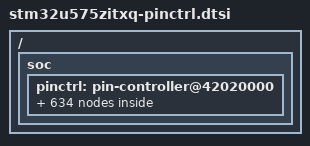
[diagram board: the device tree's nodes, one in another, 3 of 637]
/*
 * NOTE: Autogenerated file using genpinctrl.py
 *
 * SPDX-License-Identifier: Apache-2.0
 */

#include <zephyr/dt-bindings/pinctrl/stm32-pinctrl.h>

/ {
	soc {
		pinctrl: pin-controller@42020000 {

			/* ADC_IN / ADC_INN / ADC_INP */

			/omit-if-no-ref/ adc1_in5_pa0: adc1_in5_pa0 {
				pinmux = <STM32_PINMUX('A', 0, ANALOG)>;
			};

			/omit-if-no-ref/ adc1_in6_pa1: adc1_in6_pa1 {
				pinmux = <STM32_PINMUX('A', 1, ANALOG)>;
			};

			/omit-if-no-ref/ adc1_in7_pa2: adc1_in7_pa2 {
				pinmux = <STM32_PINMUX('A', 2, ANALOG)>;
			};

			/omit-if-no-ref/ adc1_in8_pa3: adc1_in8_pa3 {
				pinmux = <STM32_PINMUX('A', 3, ANALOG)>;
			};

			/omit-if-no-ref/ adc1_in9_pa4: adc1_in9_pa4 {
				pinmux = <STM32_PINMUX('A', 4, ANALOG)>;
			};

			/omit-if-no-ref/ adc1_in10_pa5: adc1_in10_pa5 {
				pinmux = <STM32_PINMUX('A', 5, ANALOG)>;
			};

			/omit-if-no-ref/ adc1_in11_pa6: adc1_in11_pa6 {
				pinmux = <STM32_PINMUX('A', 6, ANALOG)>;
			};

			/omit-if-no-ref/ adc1_in12_pa7: adc1_in12_pa7 {
				pinmux = <STM32_PINMUX('A', 7, ANALOG)>;
			};

			/omit-if-no-ref/ adc1_in15_pb0: adc1_in15_pb0 {
				pinmux = <STM32_PINMUX('B', 0, ANALOG)>;
			};

			/omit-if-no-ref/ adc1_in16_pb1: adc1_in16_pb1 {
				pinmux = <STM32_PINMUX('B', 1, ANALOG)>;
			};

			/omit-if-no-ref/ adc1_in17_pb2: adc1_in17_pb2 {
				pinmux = <STM32_PINMUX('B', 2, ANALOG)>;
			};

			/omit-if-no-ref/ adc1_in1_pc0: adc1_in1_pc0 {
				pinmux = <STM32_PINMUX('C', 0, ANALOG)>;
			};

			/omit-if-no-ref/ adc1_in2_pc1: adc1_in2_pc1 {
				pinmux = <STM32_PINMUX('C', 1, ANALOG)>;
			};

			/omit-if-no-ref/ adc1_in3_pc2: adc1_in3_pc2 {
				pinmux = <STM32_PINMUX('C', 2, ANALOG)>;
			};

			/omit-if-no-ref/ adc1_in4_pc3: adc1_in4_pc3 {
				pinmux = <STM32_PINMUX('C', 3, ANALOG)>;
			};

			/omit-if-no-ref/ adc4_in9_pa4: adc4_in9_pa4 {
				pinmux = <STM32_PINMUX('A', 4, ANALOG)>;
			};

			/omit-if-no-ref/ adc4_in10_pa5: adc4_in10_pa5 {
				pinmux = <STM32_PINMUX('A', 5, ANALOG)>;
			};

			/omit-if-no-ref/ adc4_in11_pa6: adc4_in11_pa6 {
				pinmux = <STM32_PINMUX('A', 6, ANALOG)>;
			};

			/omit-if-no-ref/ adc4_in20_pa7: adc4_in20_pa7 {
				pinmux = <STM32_PINMUX('A', 7, ANALOG)>;
			};

			/omit-if-no-ref/ adc4_in18_pb0: adc4_in18_pb0 {
				pinmux = <STM32_PINMUX('B', 0, ANALOG)>;
			};

			/omit-if-no-ref/ adc4_in19_pb1: adc4_in19_pb1 {
				pinmux = <STM32_PINMUX('B', 1, ANALOG)>;
			};

			/omit-if-no-ref/ adc4_in1_pc0: adc4_in1_pc0 {
				pinmux = <STM32_PINMUX('C', 0, ANALOG)>;
			};

			/omit-if-no-ref/ adc4_in2_pc1: adc4_in2_pc1 {
				pinmux = <STM32_PINMUX('C', 1, ANALOG)>;
			};

			/omit-if-no-ref/ adc4_in3_pc2: adc4_in3_pc2 {
				pinmux = <STM32_PINMUX('C', 2, ANALOG)>;
			};

			/omit-if-no-ref/ adc4_in4_pc3: adc4_in4_pc3 {
				pinmux = <STM32_PINMUX('C', 3, ANALOG)>;
			};

			/omit-if-no-ref/ adc4_in15_pd11: adc4_in15_pd11 {
				pinmux = <STM32_PINMUX('D', 11, ANALOG)>;
			};

			/omit-if-no-ref/ adc4_in16_pd12: adc4_in16_pd12 {
				pinmux = <STM32_PINMUX('D', 12, ANALOG)>;
			};

			/omit-if-no-ref/ adc4_in17_pd13: adc4_in17_pd13 {
				pinmux = <STM32_PINMUX('D', 13, ANALOG)>;
			};

			/omit-if-no-ref/ adc4_in5_pf14: adc4_in5_pf14 {
				pinmux = <STM32_PINMUX('F', 14, ANALOG)>;
			};

			/omit-if-no-ref/ adc4_in6_pf15: adc4_in6_pf15 {
				pinmux = <STM32_PINMUX('F', 15, ANALOG)>;
			};

			/omit-if-no-ref/ adc4_in7_pg0: adc4_in7_pg0 {
				pinmux = <STM32_PINMUX('G', 0, ANALOG)>;
			};

			/omit-if-no-ref/ adc4_in8_pg1: adc4_in8_pg1 {
				pinmux = <STM32_PINMUX('G', 1, ANALOG)>;
			};

			/* Analog */

			/omit-if-no-ref/ analog_pa0: analog_pa0 {
				pinmux = <STM32_PINMUX('A', 0, ANALOG)>;
			};

			/omit-if-no-ref/ analog_pa1: analog_pa1 {
				pinmux = <STM32_PINMUX('A', 1, ANALOG)>;
			};

			/omit-if-no-ref/ analog_pa2: analog_pa2 {
				pinmux = <STM32_PINMUX('A', 2, ANALOG)>;
			};

			/omit-if-no-ref/ analog_pa3: analog_pa3 {
				pinmux = <STM32_PINMUX('A', 3, ANALOG)>;
			};

			/omit-if-no-ref/ analog_pa4: analog_pa4 {
				pinmux = <STM32_PINMUX('A', 4, ANALOG)>;
			};

			/omit-if-no-ref/ analog_pa5: analog_pa5 {
				pinmux = <STM32_PINMUX('A', 5, ANALOG)>;
			};

			/omit-if-no-ref/ analog_pa6: analog_pa6 {
				pinmux = <STM32_PINMUX('A', 6, ANALOG)>;
			};

			/omit-if-no-ref/ analog_pa7: analog_pa7 {
				pinmux = <STM32_PINMUX('A', 7, ANALOG)>;
			};

			/omit-if-no-ref/ analog_pa8: analog_pa8 {
				pinmux = <STM32_PINMUX('A', 8, ANALOG)>;
			};

			/omit-if-no-ref/ analog_pa9: analog_pa9 {
				pinmux = <STM32_PINMUX('A', 9, ANALOG)>;
			};

			/omit-if-no-ref/ analog_pa10: analog_pa10 {
				pinmux = <STM32_PINMUX('A', 10, ANALOG)>;
			};

			/omit-if-no-ref/ analog_pa11: analog_pa11 {
				pinmux = <STM32_PINMUX('A', 11, ANALOG)>;
			};

			/omit-if-no-ref/ analog_pa12: analog_pa12 {
				pinmux = <STM32_PINMUX('A', 12, ANALOG)>;
			};

			/omit-if-no-ref/ analog_pa13: analog_pa13 {
				pinmux = <STM32_PINMUX('A', 13, ANALOG)>;
			};

			/omit-if-no-ref/ analog_pa14: analog_pa14 {
				pinmux = <STM32_PINMUX('A', 14, ANALOG)>;
			};

			/omit-if-no-ref/ analog_pa15: analog_pa15 {
				pinmux = <STM32_PINMUX('A', 15, ANALOG)>;
			};

			/omit-if-no-ref/ analog_pb0: analog_pb0 {
				pinmux = <STM32_PINMUX('B', 0, ANALOG)>;
			};

			/omit-if-no-ref/ analog_pb1: analog_pb1 {
				pinmux = <STM32_PINMUX('B', 1, ANALOG)>;
			};

			/omit-if-no-ref/ analog_pb2: analog_pb2 {
				pinmux = <STM32_PINMUX('B', 2, ANALOG)>;
			};

			/omit-if-no-ref/ analog_pb3: analog_pb3 {
				pinmux = <STM32_PINMUX('B', 3, ANALOG)>;
			};

			/omit-if-no-ref/ analog_pb4: analog_pb4 {
				pinmux = <STM32_PINMUX('B', 4, ANALOG)>;
			};

			/omit-if-no-ref/ analog_pb5: analog_pb5 {
				pinmux = <STM32_PINMUX('B', 5, ANALOG)>;
			};

			/omit-if-no-ref/ analog_pb6: analog_pb6 {
				pinmux = <STM32_PINMUX('B', 6, ANALOG)>;
			};

			/omit-if-no-ref/ analog_pb7: analog_pb7 {
				pinmux = <STM32_PINMUX('B', 7, ANALOG)>;
			};

			/omit-if-no-ref/ analog_pb8: analog_pb8 {
				pinmux = <STM32_PINMUX('B', 8, ANALOG)>;
			};

			/omit-if-no-ref/ analog_pb9: analog_pb9 {
				pinmux = <STM32_PINMUX('B', 9, ANALOG)>;
			};

			/omit-if-no-ref/ analog_pb10: analog_pb10 {
				pinmux = <STM32_PINMUX('B', 10, ANALOG)>;
			};

			/omit-if-no-ref/ analog_pb11: analog_pb11 {
				pinmux = <STM32_PINMUX('B', 11, ANALOG)>;
			};

			/omit-if-no-ref/ analog_pb13: analog_pb13 {
				pinmux = <STM32_PINMUX('B', 13, ANALOG)>;
			};

			/omit-if-no-ref/ analog_pb14: analog_pb14 {
				pinmux = <STM32_PINMUX('B', 14, ANALOG)>;
			};

			/omit-if-no-ref/ analog_pb15: analog_pb15 {
				pinmux = <STM32_PINMUX('B', 15, ANALOG)>;
			};

			/omit-if-no-ref/ analog_pc0: analog_pc0 {
				pinmux = <STM32_PINMUX('C', 0, ANALOG)>;
			};

			/omit-if-no-ref/ analog_pc1: analog_pc1 {
				pinmux = <STM32_PINMUX('C', 1, ANALOG)>;
			};

			/omit-if-no-ref/ analog_pc2: analog_pc2 {
				pinmux = <STM32_PINMUX('C', 2, ANALOG)>;
			};

			/omit-if-no-ref/ analog_pc3: analog_pc3 {
				pinmux = <STM32_PINMUX('C', 3, ANALOG)>;
			};

			/omit-if-no-ref/ analog_pc6: analog_pc6 {
				pinmux = <STM32_PINMUX('C', 6, ANALOG)>;
			};

			/omit-if-no-ref/ analog_pc7: analog_pc7 {
				pinmux = <STM32_PINMUX('C', 7, ANALOG)>;
			};

			/omit-if-no-ref/ analog_pc8: analog_pc8 {
				pinmux = <STM32_PINMUX('C', 8, ANALOG)>;
			};

			/omit-if-no-ref/ analog_pc9: analog_pc9 {
				pinmux = <STM32_PINMUX('C', 9, ANALOG)>;
			};

			/omit-if-no-ref/ analog_pc10: analog_pc10 {
				pinmux = <STM32_PINMUX('C', 10, ANALOG)>;
			};

			/omit-if-no-ref/ analog_pc11: analog_pc11 {
				pinmux = <STM32_PINMUX('C', 11, ANALOG)>;
			};

			/omit-if-no-ref/ analog_pc12: analog_pc12 {
				pinmux = <STM32_PINMUX('C', 12, ANALOG)>;
			};

			/omit-if-no-ref/ analog_pc13: analog_pc13 {
				pinmux = <STM32_PINMUX('C', 13, ANALOG)>;
			};

			/omit-if-no-ref/ analog_pc14: analog_pc14 {
				pinmux = <STM32_PINMUX('C', 14, ANALOG)>;
			};

			/omit-if-no-ref/ analog_pc15: analog_pc15 {
				pinmux = <STM32_PINMUX('C', 15, ANALOG)>;
			};

			/omit-if-no-ref/ analog_pd0: analog_pd0 {
				pinmux = <STM32_PINMUX('D', 0, ANALOG)>;
			};

			/omit-if-no-ref/ analog_pd1: analog_pd1 {
				pinmux = <STM32_PINMUX('D', 1, ANALOG)>;
			};

			/omit-if-no-ref/ analog_pd2: analog_pd2 {
				pinmux = <STM32_PINMUX('D', 2, ANALOG)>;
			};

			/omit-if-no-ref/ analog_pd3: analog_pd3 {
				pinmux = <STM32_PINMUX('D', 3, ANALOG)>;
			};

			/omit-if-no-ref/ analog_pd4: analog_pd4 {
				pinmux = <STM32_PINMUX('D', 4, ANALOG)>;
			};

			/omit-if-no-ref/ analog_pd5: analog_pd5 {
				pinmux = <STM32_PINMUX('D', 5, ANALOG)>;
			};

			/omit-if-no-ref/ analog_pd6: analog_pd6 {
				pinmux = <STM32_PINMUX('D', 6, ANALOG)>;
			};

			/omit-if-no-ref/ analog_pd7: analog_pd7 {
				pinmux = <STM32_PINMUX('D', 7, ANALOG)>;
			};

			/omit-if-no-ref/ analog_pd8: analog_pd8 {
				pinmux = <STM32_PINMUX('D', 8, ANALOG)>;
			};

			/omit-if-no-ref/ analog_pd9: analog_pd9 {
				pinmux = <STM32_PINMUX('D', 9, ANALOG)>;
			};

			/omit-if-no-ref/ analog_pd10: analog_pd10 {
				pinmux = <STM32_PINMUX('D', 10, ANALOG)>;
			};

			/omit-if-no-ref/ analog_pd11: analog_pd11 {
				pinmux = <STM32_PINMUX('D', 11, ANALOG)>;
			};

			/omit-if-no-ref/ analog_pd12: analog_pd12 {
				pinmux = <STM32_PINMUX('D', 12, ANALOG)>;
			};

			/omit-if-no-ref/ analog_pd13: analog_pd13 {
				pinmux = <STM32_PINMUX('D', 13, ANALOG)>;
			};

			/omit-if-no-ref/ analog_pd14: analog_pd14 {
				pinmux = <STM32_PINMUX('D', 14, ANALOG)>;
			};

			/omit-if-no-ref/ analog_pd15: analog_pd15 {
				pinmux = <STM32_PINMUX('D', 15, ANALOG)>;
			};

			/omit-if-no-ref/ analog_pe0: analog_pe0 {
				pinmux = <STM32_PINMUX('E', 0, ANALOG)>;
			};

			/omit-if-no-ref/ analog_pe1: analog_pe1 {
				pinmux = <STM32_PINMUX('E', 1, ANALOG)>;
			};

			/omit-if-no-ref/ analog_pe2: analog_pe2 {
				pinmux = <STM32_PINMUX('E', 2, ANALOG)>;
			};

			/omit-if-no-ref/ analog_pe3: analog_pe3 {
				pinmux = <STM32_PINMUX('E', 3, ANALOG)>;
			};

			/omit-if-no-ref/ analog_pe4: analog_pe4 {
				pinmux = <STM32_PINMUX('E', 4, ANALOG)>;
			};

			/omit-if-no-ref/ analog_pe5: analog_pe5 {
				pinmux = <STM32_PINMUX('E', 5, ANALOG)>;
			};

			/omit-if-no-ref/ analog_pe6: analog_pe6 {
				pinmux = <STM32_PINMUX('E', 6, ANALOG)>;
			};

			/omit-if-no-ref/ analog_pe7: analog_pe7 {
				pinmux = <STM32_PINMUX('E', 7, ANALOG)>;
			};

			/omit-if-no-ref/ analog_pe8: analog_pe8 {
				pinmux = <STM32_PINMUX('E', 8, ANALOG)>;
			};

			/omit-if-no-ref/ analog_pe9: analog_pe9 {
				pinmux = <STM32_PINMUX('E', 9, ANALOG)>;
			};

			/omit-if-no-ref/ analog_pe10: analog_pe10 {
				pinmux = <STM32_PINMUX('E', 10, ANALOG)>;
			};

			/omit-if-no-ref/ analog_pe11: analog_pe11 {
				pinmux = <STM32_PINMUX('E', 11, ANALOG)>;
			};

			/omit-if-no-ref/ analog_pe12: analog_pe12 {
				pinmux = <STM32_PINMUX('E', 12, ANALOG)>;
			};

			/omit-if-no-ref/ analog_pe13: analog_pe13 {
				pinmux = <STM32_PINMUX('E', 13, ANALOG)>;
			};

			/omit-if-no-ref/ analog_pe14: analog_pe14 {
				pinmux = <STM32_PINMUX('E', 14, ANALOG)>;
			};

			/omit-if-no-ref/ analog_pe15: analog_pe15 {
				pinmux = <STM32_PINMUX('E', 15, ANALOG)>;
			};

			/omit-if-no-ref/ analog_pf0: analog_pf0 {
				pinmux = <STM32_PINMUX('F', 0, ANALOG)>;
			};

			/omit-if-no-ref/ analog_pf1: analog_pf1 {
				pinmux = <STM32_PINMUX('F', 1, ANALOG)>;
			};

			/omit-if-no-ref/ analog_pf2: analog_pf2 {
				pinmux = <STM32_PINMUX('F', 2, ANALOG)>;
			};

			/omit-if-no-ref/ analog_pf3: analog_pf3 {
				pinmux = <STM32_PINMUX('F', 3, ANALOG)>;
			};

			/omit-if-no-ref/ analog_pf4: analog_pf4 {
				pinmux = <STM32_PINMUX('F', 4, ANALOG)>;
			};

			/omit-if-no-ref/ analog_pf5: analog_pf5 {
				pinmux = <STM32_PINMUX('F', 5, ANALOG)>;
			};

			/omit-if-no-ref/ analog_pf6: analog_pf6 {
				pinmux = <STM32_PINMUX('F', 6, ANALOG)>;
			};

			/omit-if-no-ref/ analog_pf7: analog_pf7 {
				pinmux = <STM32_PINMUX('F', 7, ANALOG)>;
			};

			/omit-if-no-ref/ analog_pf8: analog_pf8 {
				pinmux = <STM32_PINMUX('F', 8, ANALOG)>;
			};

			/omit-if-no-ref/ analog_pf9: analog_pf9 {
				pinmux = <STM32_PINMUX('F', 9, ANALOG)>;
			};

			/omit-if-no-ref/ analog_pf10: analog_pf10 {
				pinmux = <STM32_PINMUX('F', 10, ANALOG)>;
			};

			/omit-if-no-ref/ analog_pf11: analog_pf11 {
				pinmux = <STM32_PINMUX('F', 11, ANALOG)>;
			};

			/omit-if-no-ref/ analog_pf12: analog_pf12 {
				pinmux = <STM32_PINMUX('F', 12, ANALOG)>;
			};

			/omit-if-no-ref/ analog_pf13: analog_pf13 {
				pinmux = <STM32_PINMUX('F', 13, ANALOG)>;
			};

			/omit-if-no-ref/ analog_pf14: analog_pf14 {
				pinmux = <STM32_PINMUX('F', 14, ANALOG)>;
			};

			/omit-if-no-ref/ analog_pf15: analog_pf15 {
				pinmux = <STM32_PINMUX('F', 15, ANALOG)>;
			};

			/omit-if-no-ref/ analog_pg0: analog_pg0 {
				pinmux = <STM32_PINMUX('G', 0, ANALOG)>;
			};

			/omit-if-no-ref/ analog_pg1: analog_pg1 {
				pinmux = <STM32_PINMUX('G', 1, ANALOG)>;
			};

			/omit-if-no-ref/ analog_pg2: analog_pg2 {
				pinmux = <STM32_PINMUX('G', 2, ANALOG)>;
			};

			/omit-if-no-ref/ analog_pg3: analog_pg3 {
				pinmux = <STM32_PINMUX('G', 3, ANALOG)>;
			};

			/omit-if-no-ref/ analog_pg4: analog_pg4 {
				pinmux = <STM32_PINMUX('G', 4, ANALOG)>;
			};

			/omit-if-no-ref/ analog_pg5: analog_pg5 {
				pinmux = <STM32_PINMUX('G', 5, ANALOG)>;
			};

			/omit-if-no-ref/ analog_pg6: analog_pg6 {
				pinmux = <STM32_PINMUX('G', 6, ANALOG)>;
			};

			/omit-if-no-ref/ analog_pg7: analog_pg7 {
				pinmux = <STM32_PINMUX('G', 7, ANALOG)>;
			};

			/omit-if-no-ref/ analog_pg8: analog_pg8 {
				pinmux = <STM32_PINMUX('G', 8, ANALOG)>;
			};

			/omit-if-no-ref/ analog_pg9: analog_pg9 {
				pinmux = <STM32_PINMUX('G', 9, ANALOG)>;
			};

			/omit-if-no-ref/ analog_pg10: analog_pg10 {
				pinmux = <STM32_PINMUX('G', 10, ANALOG)>;
			};

			/omit-if-no-ref/ analog_pg12: analog_pg12 {
				pinmux = <STM32_PINMUX('G', 12, ANALOG)>;
			};

			/omit-if-no-ref/ analog_pg13: analog_pg13 {
				pinmux = <STM32_PINMUX('G', 13, ANALOG)>;
			};

			/omit-if-no-ref/ analog_pg14: analog_pg14 {
				pinmux = <STM32_PINMUX('G', 14, ANALOG)>;
			};

			/omit-if-no-ref/ analog_pg15: analog_pg15 {
				pinmux = <STM32_PINMUX('G', 15, ANALOG)>;
			};

			/omit-if-no-ref/ analog_ph0: analog_ph0 {
				pinmux = <STM32_PINMUX('H', 0, ANALOG)>;
			};

			/omit-if-no-ref/ analog_ph1: analog_ph1 {
				pinmux = <STM32_PINMUX('H', 1, ANALOG)>;
			};

			/omit-if-no-ref/ analog_ph3: analog_ph3 {
				pinmux = <STM32_PINMUX('H', 3, ANALOG)>;
			};

			/* DAC_OUT */

			/omit-if-no-ref/ dac1_out1_pa4: dac1_out1_pa4 {
				pinmux = <STM32_PINMUX('A', 4, ANALOG)>;
			};

			/omit-if-no-ref/ dac1_out2_pa5: dac1_out2_pa5 {
				pinmux = <STM32_PINMUX('A', 5, ANALOG)>;
			};

			/* DCMI */

			/omit-if-no-ref/ dcmi_hsync_pa4: dcmi_hsync_pa4 {
				pinmux = <STM32_PINMUX('A', 4, AF10)>;
				slew-rate = "very-high-speed";
			};

			/omit-if-no-ref/ dcmi_pixclk_pa6: dcmi_pixclk_pa6 {
				pinmux = <STM32_PINMUX('A', 6, AF4)>;
				slew-rate = "very-high-speed";
			};

			/omit-if-no-ref/ dcmi_d0_pa9: dcmi_d0_pa9 {
				pinmux = <STM32_PINMUX('A', 9, AF5)>;
				slew-rate = "very-high-speed";
			};

			/omit-if-no-ref/ dcmi_d1_pa10: dcmi_d1_pa10 {
				pinmux = <STM32_PINMUX('A', 10, AF5)>;
				slew-rate = "very-high-speed";
			};

			/omit-if-no-ref/ dcmi_d5_pb6: dcmi_d5_pb6 {
				pinmux = <STM32_PINMUX('B', 6, AF10)>;
				slew-rate = "very-high-speed";
			};

			/omit-if-no-ref/ dcmi_vsync_pb7: dcmi_vsync_pb7 {
				pinmux = <STM32_PINMUX('B', 7, AF10)>;
				slew-rate = "very-high-speed";
			};

			/omit-if-no-ref/ dcmi_d6_pb8: dcmi_d6_pb8 {
				pinmux = <STM32_PINMUX('B', 8, AF10)>;
				slew-rate = "very-high-speed";
			};

			/omit-if-no-ref/ dcmi_d7_pb9: dcmi_d7_pb9 {
				pinmux = <STM32_PINMUX('B', 9, AF10)>;
				slew-rate = "very-high-speed";
			};

			/omit-if-no-ref/ dcmi_d0_pc6: dcmi_d0_pc6 {
				pinmux = <STM32_PINMUX('C', 6, AF10)>;
				slew-rate = "very-high-speed";
			};

			/omit-if-no-ref/ dcmi_d1_pc7: dcmi_d1_pc7 {
				pinmux = <STM32_PINMUX('C', 7, AF10)>;
				slew-rate = "very-high-speed";
			};

			/omit-if-no-ref/ dcmi_d2_pc8: dcmi_d2_pc8 {
				pinmux = <STM32_PINMUX('C', 8, AF10)>;
				slew-rate = "very-high-speed";
			};

			/omit-if-no-ref/ dcmi_d3_pc9: dcmi_d3_pc9 {
				pinmux = <STM32_PINMUX('C', 9, AF4)>;
				slew-rate = "very-high-speed";
			};

			/omit-if-no-ref/ dcmi_d2_pc11: dcmi_d2_pc11 {
				pinmux = <STM32_PINMUX('C', 11, AF4)>;
				slew-rate = "very-high-speed";
			};

			/omit-if-no-ref/ dcmi_d4_pc11: dcmi_d4_pc11 {
				pinmux = <STM32_PINMUX('C', 11, AF10)>;
				slew-rate = "very-high-speed";
			};

			/omit-if-no-ref/ dcmi_d5_pd3: dcmi_d5_pd3 {
				pinmux = <STM32_PINMUX('D', 3, AF4)>;
				slew-rate = "very-high-speed";
			};

			/omit-if-no-ref/ dcmi_hsync_pd8: dcmi_hsync_pd8 {
				pinmux = <STM32_PINMUX('D', 8, AF10)>;
				slew-rate = "very-high-speed";
			};

			/omit-if-no-ref/ dcmi_pixclk_pd9: dcmi_pixclk_pd9 {
				pinmux = <STM32_PINMUX('D', 9, AF10)>;
				slew-rate = "very-high-speed";
			};

			/omit-if-no-ref/ dcmi_d2_pe0: dcmi_d2_pe0 {
				pinmux = <STM32_PINMUX('E', 0, AF10)>;
				slew-rate = "very-high-speed";
			};

			/omit-if-no-ref/ dcmi_d3_pe1: dcmi_d3_pe1 {
				pinmux = <STM32_PINMUX('E', 1, AF10)>;
				slew-rate = "very-high-speed";
			};

			/omit-if-no-ref/ dcmi_d4_pe4: dcmi_d4_pe4 {
				pinmux = <STM32_PINMUX('E', 4, AF10)>;
				slew-rate = "very-high-speed";
			};

			/omit-if-no-ref/ dcmi_d6_pe5: dcmi_d6_pe5 {
				pinmux = <STM32_PINMUX('E', 5, AF10)>;
				slew-rate = "very-high-speed";
			};

			/omit-if-no-ref/ dcmi_d7_pe6: dcmi_d7_pe6 {
				pinmux = <STM32_PINMUX('E', 6, AF10)>;
				slew-rate = "very-high-speed";
			};

			/* FDCAN_RX */

			/omit-if-no-ref/ fdcan1_rx_pa11: fdcan1_rx_pa11 {
				pinmux = <STM32_PINMUX('A', 11, AF9)>;
			};

			/omit-if-no-ref/ fdcan1_rx_pb8: fdcan1_rx_pb8 {
				pinmux = <STM32_PINMUX('B', 8, AF9)>;
			};

			/omit-if-no-ref/ fdcan1_rx_pd0: fdcan1_rx_pd0 {
				pinmux = <STM32_PINMUX('D', 0, AF9)>;
			};

			/omit-if-no-ref/ fdcan1_rx_pf7: fdcan1_rx_pf7 {
				pinmux = <STM32_PINMUX('F', 7, AF9)>;
			};

			/* FDCAN_TX */

			/omit-if-no-ref/ fdcan1_tx_pa12: fdcan1_tx_pa12 {
				pinmux = <STM32_PINMUX('A', 12, AF9)>;
			};

			/omit-if-no-ref/ fdcan1_tx_pb9: fdcan1_tx_pb9 {
				pinmux = <STM32_PINMUX('B', 9, AF9)>;
			};

			/omit-if-no-ref/ fdcan1_tx_pd1: fdcan1_tx_pd1 {
				pinmux = <STM32_PINMUX('D', 1, AF9)>;
			};

			/omit-if-no-ref/ fdcan1_tx_pf8: fdcan1_tx_pf8 {
				pinmux = <STM32_PINMUX('F', 8, AF9)>;
			};

			/* FMC */

			/omit-if-no-ref/ fmc_nl_pb7: fmc_nl_pb7 {
				pinmux = <STM32_PINMUX('B', 7, AF12)>;
				bias-pull-up;
				slew-rate = "very-high-speed";
			};

			/omit-if-no-ref/ fmc_nbl1_pb15: fmc_nbl1_pb15 {
				pinmux = <STM32_PINMUX('B', 15, AF11)>;
				bias-pull-up;
				slew-rate = "very-high-speed";
			};

			/omit-if-no-ref/ fmc_d2_pd0: fmc_d2_pd0 {
				pinmux = <STM32_PINMUX('D', 0, AF12)>;
				bias-pull-up;
				slew-rate = "very-high-speed";
			};

			/omit-if-no-ref/ fmc_d3_pd1: fmc_d3_pd1 {
				pinmux = <STM32_PINMUX('D', 1, AF12)>;
				bias-pull-up;
				slew-rate = "very-high-speed";
			};

			/omit-if-no-ref/ fmc_clk_pd3: fmc_clk_pd3 {
				pinmux = <STM32_PINMUX('D', 3, AF12)>;
				bias-pull-up;
				slew-rate = "very-high-speed";
			};

			/omit-if-no-ref/ fmc_noe_pd4: fmc_noe_pd4 {
				pinmux = <STM32_PINMUX('D', 4, AF12)>;
				bias-pull-up;
				slew-rate = "very-high-speed";
			};

			/omit-if-no-ref/ fmc_nwe_pd5: fmc_nwe_pd5 {
				pinmux = <STM32_PINMUX('D', 5, AF12)>;
				bias-pull-up;
				slew-rate = "very-high-speed";
			};

			/omit-if-no-ref/ fmc_nwait_pd6: fmc_nwait_pd6 {
				pinmux = <STM32_PINMUX('D', 6, AF12)>;
				bias-pull-up;
				slew-rate = "very-high-speed";
			};

			/omit-if-no-ref/ fmc_nce_pd7: fmc_nce_pd7 {
				pinmux = <STM32_PINMUX('D', 7, AF12)>;
				bias-pull-up;
				slew-rate = "very-high-speed";
			};

			/omit-if-no-ref/ fmc_ne1_pd7: fmc_ne1_pd7 {
				pinmux = <STM32_PINMUX('D', 7, AF12)>;
				bias-pull-up;
				slew-rate = "very-high-speed";
			};

			/omit-if-no-ref/ fmc_d13_pd8: fmc_d13_pd8 {
				pinmux = <STM32_PINMUX('D', 8, AF12)>;
				bias-pull-up;
				slew-rate = "very-high-speed";
			};

			/omit-if-no-ref/ fmc_d14_pd9: fmc_d14_pd9 {
				pinmux = <STM32_PINMUX('D', 9, AF12)>;
				bias-pull-up;
				slew-rate = "very-high-speed";
			};

			/omit-if-no-ref/ fmc_d15_pd10: fmc_d15_pd10 {
				pinmux = <STM32_PINMUX('D', 10, AF12)>;
				bias-pull-up;
				slew-rate = "very-high-speed";
			};

			/omit-if-no-ref/ fmc_a16_pd11: fmc_a16_pd11 {
				pinmux = <STM32_PINMUX('D', 11, AF12)>;
				bias-pull-up;
				slew-rate = "very-high-speed";
			};

			/omit-if-no-ref/ fmc_a17_pd12: fmc_a17_pd12 {
				pinmux = <STM32_PINMUX('D', 12, AF12)>;
				bias-pull-up;
				slew-rate = "very-high-speed";
			};

			/omit-if-no-ref/ fmc_a18_pd13: fmc_a18_pd13 {
				pinmux = <STM32_PINMUX('D', 13, AF12)>;
				bias-pull-up;
				slew-rate = "very-high-speed";
			};

			/omit-if-no-ref/ fmc_d0_pd14: fmc_d0_pd14 {
				pinmux = <STM32_PINMUX('D', 14, AF12)>;
				bias-pull-up;
				slew-rate = "very-high-speed";
			};

			/omit-if-no-ref/ fmc_d1_pd15: fmc_d1_pd15 {
				pinmux = <STM32_PINMUX('D', 15, AF12)>;
				bias-pull-up;
				slew-rate = "very-high-speed";
			};

			/omit-if-no-ref/ fmc_nbl0_pe0: fmc_nbl0_pe0 {
				pinmux = <STM32_PINMUX('E', 0, AF12)>;
				bias-pull-up;
				slew-rate = "very-high-speed";
			};

			/omit-if-no-ref/ fmc_nbl1_pe1: fmc_nbl1_pe1 {
				pinmux = <STM32_PINMUX('E', 1, AF12)>;
				bias-pull-up;
				slew-rate = "very-high-speed";
			};

			/omit-if-no-ref/ fmc_a23_pe2: fmc_a23_pe2 {
				pinmux = <STM32_PINMUX('E', 2, AF12)>;
				bias-pull-up;
				slew-rate = "very-high-speed";
			};

			/omit-if-no-ref/ fmc_a19_pe3: fmc_a19_pe3 {
				pinmux = <STM32_PINMUX('E', 3, AF12)>;
				bias-pull-up;
				slew-rate = "very-high-speed";
			};

			/omit-if-no-ref/ fmc_a20_pe4: fmc_a20_pe4 {
				pinmux = <STM32_PINMUX('E', 4, AF12)>;
				bias-pull-up;
				slew-rate = "very-high-speed";
			};

			/omit-if-no-ref/ fmc_a21_pe5: fmc_a21_pe5 {
				pinmux = <STM32_PINMUX('E', 5, AF12)>;
				bias-pull-up;
				slew-rate = "very-high-speed";
			};

			/omit-if-no-ref/ fmc_a22_pe6: fmc_a22_pe6 {
				pinmux = <STM32_PINMUX('E', 6, AF12)>;
				bias-pull-up;
				slew-rate = "very-high-speed";
			};

			/omit-if-no-ref/ fmc_d4_pe7: fmc_d4_pe7 {
				pinmux = <STM32_PINMUX('E', 7, AF12)>;
				bias-pull-up;
				slew-rate = "very-high-speed";
			};

			/omit-if-no-ref/ fmc_d5_pe8: fmc_d5_pe8 {
				pinmux = <STM32_PINMUX('E', 8, AF12)>;
				bias-pull-up;
				slew-rate = "very-high-speed";
			};

			/omit-if-no-ref/ fmc_d6_pe9: fmc_d6_pe9 {
				pinmux = <STM32_PINMUX('E', 9, AF12)>;
				bias-pull-up;
				slew-rate = "very-high-speed";
			};

			/omit-if-no-ref/ fmc_d7_pe10: fmc_d7_pe10 {
				pinmux = <STM32_PINMUX('E', 10, AF12)>;
				bias-pull-up;
				slew-rate = "very-high-speed";
			};

			/omit-if-no-ref/ fmc_d8_pe11: fmc_d8_pe11 {
				pinmux = <STM32_PINMUX('E', 11, AF12)>;
				bias-pull-up;
				slew-rate = "very-high-speed";
			};

			/omit-if-no-ref/ fmc_d9_pe12: fmc_d9_pe12 {
				pinmux = <STM32_PINMUX('E', 12, AF12)>;
				bias-pull-up;
				slew-rate = "very-high-speed";
			};

			/omit-if-no-ref/ fmc_d10_pe13: fmc_d10_pe13 {
				pinmux = <STM32_PINMUX('E', 13, AF12)>;
				bias-pull-up;
				slew-rate = "very-high-speed";
			};

			/omit-if-no-ref/ fmc_d11_pe14: fmc_d11_pe14 {
				pinmux = <STM32_PINMUX('E', 14, AF12)>;
				bias-pull-up;
				slew-rate = "very-high-speed";
			};

			/omit-if-no-ref/ fmc_d12_pe15: fmc_d12_pe15 {
				pinmux = <STM32_PINMUX('E', 15, AF12)>;
				bias-pull-up;
				slew-rate = "very-high-speed";
			};

			/omit-if-no-ref/ fmc_a0_pf0: fmc_a0_pf0 {
				pinmux = <STM32_PINMUX('F', 0, AF12)>;
				bias-pull-up;
				slew-rate = "very-high-speed";
			};

			/omit-if-no-ref/ fmc_a1_pf1: fmc_a1_pf1 {
				pinmux = <STM32_PINMUX('F', 1, AF12)>;
				bias-pull-up;
				slew-rate = "very-high-speed";
			};

			/omit-if-no-ref/ fmc_a2_pf2: fmc_a2_pf2 {
				pinmux = <STM32_PINMUX('F', 2, AF12)>;
				bias-pull-up;
				slew-rate = "very-high-speed";
			};

			/omit-if-no-ref/ fmc_a3_pf3: fmc_a3_pf3 {
				pinmux = <STM32_PINMUX('F', 3, AF12)>;
				bias-pull-up;
				slew-rate = "very-high-speed";
			};

			/omit-if-no-ref/ fmc_a4_pf4: fmc_a4_pf4 {
				pinmux = <STM32_PINMUX('F', 4, AF12)>;
				bias-pull-up;
				slew-rate = "very-high-speed";
			};

			/omit-if-no-ref/ fmc_a5_pf5: fmc_a5_pf5 {
				pinmux = <STM32_PINMUX('F', 5, AF12)>;
				bias-pull-up;
				slew-rate = "very-high-speed";
			};

			/omit-if-no-ref/ fmc_a6_pf12: fmc_a6_pf12 {
				pinmux = <STM32_PINMUX('F', 12, AF12)>;
				bias-pull-up;
				slew-rate = "very-high-speed";
			};

			/omit-if-no-ref/ fmc_a7_pf13: fmc_a7_pf13 {
				pinmux = <STM32_PINMUX('F', 13, AF12)>;
				bias-pull-up;
				slew-rate = "very-high-speed";
			};

			/omit-if-no-ref/ fmc_a8_pf14: fmc_a8_pf14 {
				pinmux = <STM32_PINMUX('F', 14, AF12)>;
				bias-pull-up;
				slew-rate = "very-high-speed";
			};

			/omit-if-no-ref/ fmc_a9_pf15: fmc_a9_pf15 {
				pinmux = <STM32_PINMUX('F', 15, AF12)>;
				bias-pull-up;
				slew-rate = "very-high-speed";
			};

			/omit-if-no-ref/ fmc_a10_pg0: fmc_a10_pg0 {
				pinmux = <STM32_PINMUX('G', 0, AF12)>;
				bias-pull-up;
				slew-rate = "very-high-speed";
			};

			/omit-if-no-ref/ fmc_a11_pg1: fmc_a11_pg1 {
				pinmux = <STM32_PINMUX('G', 1, AF12)>;
				bias-pull-up;
				slew-rate = "very-high-speed";
			};

			/omit-if-no-ref/ fmc_a12_pg2: fmc_a12_pg2 {
				pinmux = <STM32_PINMUX('G', 2, AF12)>;
				bias-pull-up;
				slew-rate = "very-high-speed";
			};

			/omit-if-no-ref/ fmc_a13_pg3: fmc_a13_pg3 {
				pinmux = <STM32_PINMUX('G', 3, AF12)>;
				bias-pull-up;
				slew-rate = "very-high-speed";
			};

			/omit-if-no-ref/ fmc_a14_pg4: fmc_a14_pg4 {
				pinmux = <STM32_PINMUX('G', 4, AF12)>;
				bias-pull-up;
				slew-rate = "very-high-speed";
			};

			/omit-if-no-ref/ fmc_a15_pg5: fmc_a15_pg5 {
				pinmux = <STM32_PINMUX('G', 5, AF12)>;
				bias-pull-up;
				slew-rate = "very-high-speed";
			};

			/omit-if-no-ref/ fmc_int_pg7: fmc_int_pg7 {
				pinmux = <STM32_PINMUX('G', 7, AF12)>;
				bias-pull-up;
				slew-rate = "very-high-speed";
			};

			/omit-if-no-ref/ fmc_nce_pg9: fmc_nce_pg9 {
				pinmux = <STM32_PINMUX('G', 9, AF12)>;
				bias-pull-up;
				slew-rate = "very-high-speed";
			};

			/omit-if-no-ref/ fmc_ne2_pg9: fmc_ne2_pg9 {
				pinmux = <STM32_PINMUX('G', 9, AF12)>;
				bias-pull-up;
				slew-rate = "very-high-speed";
			};

			/omit-if-no-ref/ fmc_ne3_pg10: fmc_ne3_pg10 {
				pinmux = <STM32_PINMUX('G', 10, AF12)>;
				bias-pull-up;
				slew-rate = "very-high-speed";
			};

			/omit-if-no-ref/ fmc_ne4_pg12: fmc_ne4_pg12 {
				pinmux = <STM32_PINMUX('G', 12, AF12)>;
				bias-pull-up;
				slew-rate = "very-high-speed";
			};

			/omit-if-no-ref/ fmc_a24_pg13: fmc_a24_pg13 {
				pinmux = <STM32_PINMUX('G', 13, AF12)>;
				bias-pull-up;
				slew-rate = "very-high-speed";
			};

			/omit-if-no-ref/ fmc_a25_pg14: fmc_a25_pg14 {
				pinmux = <STM32_PINMUX('G', 14, AF12)>;
				bias-pull-up;
				slew-rate = "very-high-speed";
			};

			/* I2C_SCL */

			/omit-if-no-ref/ i2c1_scl_pb6: i2c1_scl_pb6 {
				pinmux = <STM32_PINMUX('B', 6, AF4)>;
				bias-pull-up;
				drive-open-drain;
			};

			/omit-if-no-ref/ i2c1_scl_pb8: i2c1_scl_pb8 {
				pinmux = <STM32_PINMUX('B', 8, AF4)>;
				bias-pull-up;
				drive-open-drain;
			};

			/omit-if-no-ref/ i2c1_scl_pg14: i2c1_scl_pg14 {
				pinmux = <STM32_PINMUX('G', 14, AF4)>;
				bias-pull-up;
				drive-open-drain;
			};

			/omit-if-no-ref/ i2c2_scl_pb10: i2c2_scl_pb10 {
				pinmux = <STM32_PINMUX('B', 10, AF4)>;
				bias-pull-up;
				drive-open-drain;
			};

			/omit-if-no-ref/ i2c2_scl_pb13: i2c2_scl_pb13 {
				pinmux = <STM32_PINMUX('B', 13, AF4)>;
				bias-pull-up;
				drive-open-drain;
			};

			/omit-if-no-ref/ i2c2_scl_pf1: i2c2_scl_pf1 {
				pinmux = <STM32_PINMUX('F', 1, AF4)>;
				bias-pull-up;
				drive-open-drain;
			};

			/omit-if-no-ref/ i2c3_scl_pa7: i2c3_scl_pa7 {
				pinmux = <STM32_PINMUX('A', 7, AF4)>;
				bias-pull-up;
				drive-open-drain;
			};

			/omit-if-no-ref/ i2c3_scl_pc0: i2c3_scl_pc0 {
				pinmux = <STM32_PINMUX('C', 0, AF4)>;
				bias-pull-up;
				drive-open-drain;
			};

			/omit-if-no-ref/ i2c3_scl_pg7: i2c3_scl_pg7 {
				pinmux = <STM32_PINMUX('G', 7, AF4)>;
				bias-pull-up;
				drive-open-drain;
			};

			/omit-if-no-ref/ i2c4_scl_pb6: i2c4_scl_pb6 {
				pinmux = <STM32_PINMUX('B', 6, AF5)>;
				bias-pull-up;
				drive-open-drain;
			};

			/omit-if-no-ref/ i2c4_scl_pb10: i2c4_scl_pb10 {
				pinmux = <STM32_PINMUX('B', 10, AF3)>;
				bias-pull-up;
				drive-open-drain;
			};

			/omit-if-no-ref/ i2c4_scl_pd12: i2c4_scl_pd12 {
				pinmux = <STM32_PINMUX('D', 12, AF4)>;
				bias-pull-up;
				drive-open-drain;
			};

			/omit-if-no-ref/ i2c4_scl_pf14: i2c4_scl_pf14 {
				pinmux = <STM32_PINMUX('F', 14, AF4)>;
				bias-pull-up;
				drive-open-drain;
			};

			/* I2C_SDA */

			/omit-if-no-ref/ i2c1_sda_pb3: i2c1_sda_pb3 {
				pinmux = <STM32_PINMUX('B', 3, AF4)>;
				bias-pull-up;
				drive-open-drain;
			};

			/omit-if-no-ref/ i2c1_sda_pb7: i2c1_sda_pb7 {
				pinmux = <STM32_PINMUX('B', 7, AF4)>;
				bias-pull-up;
				drive-open-drain;
			};

			/omit-if-no-ref/ i2c1_sda_pb9: i2c1_sda_pb9 {
				pinmux = <STM32_PINMUX('B', 9, AF4)>;
				bias-pull-up;
				drive-open-drain;
			};

			/omit-if-no-ref/ i2c1_sda_pg13: i2c1_sda_pg13 {
				pinmux = <STM32_PINMUX('G', 13, AF4)>;
				bias-pull-up;
				drive-open-drain;
			};

			/omit-if-no-ref/ i2c2_sda_pb11: i2c2_sda_pb11 {
				pinmux = <STM32_PINMUX('B', 11, AF4)>;
				bias-pull-up;
				drive-open-drain;
			};

			/omit-if-no-ref/ i2c2_sda_pb14: i2c2_sda_pb14 {
				pinmux = <STM32_PINMUX('B', 14, AF4)>;
				bias-pull-up;
				drive-open-drain;
			};

			/omit-if-no-ref/ i2c2_sda_pf0: i2c2_sda_pf0 {
				pinmux = <STM32_PINMUX('F', 0, AF4)>;
				bias-pull-up;
				drive-open-drain;
			};

			/omit-if-no-ref/ i2c3_sda_pb4: i2c3_sda_pb4 {
				pinmux = <STM32_PINMUX('B', 4, AF4)>;
				bias-pull-up;
				drive-open-drain;
			};

			/omit-if-no-ref/ i2c3_sda_pc1: i2c3_sda_pc1 {
				pinmux = <STM32_PINMUX('C', 1, AF4)>;
				bias-pull-up;
				drive-open-drain;
			};

			/omit-if-no-ref/ i2c3_sda_pg8: i2c3_sda_pg8 {
				pinmux = <STM32_PINMUX('G', 8, AF4)>;
				bias-pull-up;
				drive-open-drain;
			};

			/omit-if-no-ref/ i2c4_sda_pb7: i2c4_sda_pb7 {
				pinmux = <STM32_PINMUX('B', 7, AF5)>;
				bias-pull-up;
				drive-open-drain;
			};

			/omit-if-no-ref/ i2c4_sda_pb11: i2c4_sda_pb11 {
				pinmux = <STM32_PINMUX('B', 11, AF3)>;
				bias-pull-up;
				drive-open-drain;
			};

			/omit-if-no-ref/ i2c4_sda_pd13: i2c4_sda_pd13 {
				pinmux = <STM32_PINMUX('D', 13, AF4)>;
				bias-pull-up;
				drive-open-drain;
			};

			/omit-if-no-ref/ i2c4_sda_pf15: i2c4_sda_pf15 {
				pinmux = <STM32_PINMUX('F', 15, AF4)>;
				bias-pull-up;
				drive-open-drain;
			};

			/* I2C_SMBA */

			/omit-if-no-ref/ i2c1_smba_pa1: i2c1_smba_pa1 {
				pinmux = <STM32_PINMUX('A', 1, AF4)>;
				bias-pull-up;
			};

			/omit-if-no-ref/ i2c1_smba_pa14: i2c1_smba_pa14 {
				pinmux = <STM32_PINMUX('A', 14, AF4)>;
				bias-pull-up;
			};

			/omit-if-no-ref/ i2c1_smba_pb5: i2c1_smba_pb5 {
				pinmux = <STM32_PINMUX('B', 5, AF4)>;
				bias-pull-up;
			};

			/omit-if-no-ref/ i2c1_smba_pg15: i2c1_smba_pg15 {
				pinmux = <STM32_PINMUX('G', 15, AF4)>;
				bias-pull-up;
			};

			/omit-if-no-ref/ i2c2_smba_pf2: i2c2_smba_pf2 {
				pinmux = <STM32_PINMUX('F', 2, AF4)>;
				bias-pull-up;
			};

			/omit-if-no-ref/ i2c3_smba_pb2: i2c3_smba_pb2 {
				pinmux = <STM32_PINMUX('B', 2, AF4)>;
				bias-pull-up;
			};

			/omit-if-no-ref/ i2c3_smba_pg6: i2c3_smba_pg6 {
				pinmux = <STM32_PINMUX('G', 6, AF4)>;
				bias-pull-up;
			};

			/omit-if-no-ref/ i2c4_smba_pa14: i2c4_smba_pa14 {
				pinmux = <STM32_PINMUX('A', 14, AF5)>;
				bias-pull-up;
			};

			/omit-if-no-ref/ i2c4_smba_pd11: i2c4_smba_pd11 {
				pinmux = <STM32_PINMUX('D', 11, AF4)>;
				bias-pull-up;
			};

			/omit-if-no-ref/ i2c4_smba_pf13: i2c4_smba_pf13 {
				pinmux = <STM32_PINMUX('F', 13, AF4)>;
				bias-pull-up;
			};

			/* JTAG PORT */

			/omit-if-no-ref/ debug_jtms_swdio_pa13: debug_jtms_swdio_pa13 {
				pinmux = <STM32_PINMUX('A', 13, AF0)>;
			};

			/omit-if-no-ref/ debug_jtck_swclk_pa14: debug_jtck_swclk_pa14 {
				pinmux = <STM32_PINMUX('A', 14, AF0)>;
			};

			/omit-if-no-ref/ debug_jtdi_pa15: debug_jtdi_pa15 {
				pinmux = <STM32_PINMUX('A', 15, AF0)>;
			};

			/omit-if-no-ref/ debug_jtdo_swo_pb3: debug_jtdo_swo_pb3 {
				pinmux = <STM32_PINMUX('B', 3, AF0)>;
			};

			/omit-if-no-ref/ debug_jtrst_pb4: debug_jtrst_pb4 {
				pinmux = <STM32_PINMUX('B', 4, AF0)>;
			};

			/* OCTOSPI */

			/omit-if-no-ref/ octospim_p2_ncs_pa0: octospim_p2_ncs_pa0 {
				pinmux = <STM32_PINMUX('A', 0, AF10)>;
				slew-rate = "very-high-speed";
			};

			/omit-if-no-ref/ octospim_p1_dqs_pa1: octospim_p1_dqs_pa1 {
				pinmux = <STM32_PINMUX('A', 1, AF10)>;
				slew-rate = "very-high-speed";
			};

			/omit-if-no-ref/ octospim_p1_ncs_pa2: octospim_p1_ncs_pa2 {
				pinmux = <STM32_PINMUX('A', 2, AF10)>;
				slew-rate = "very-high-speed";
			};

			/omit-if-no-ref/ octospim_p1_clk_pa3: octospim_p1_clk_pa3 {
				pinmux = <STM32_PINMUX('A', 3, AF10)>;
				slew-rate = "very-high-speed";
			};

			/omit-if-no-ref/ octospim_p1_ncs_pa4: octospim_p1_ncs_pa4 {
				pinmux = <STM32_PINMUX('A', 4, AF3)>;
				slew-rate = "very-high-speed";
			};

			/omit-if-no-ref/ octospim_p1_io3_pa6: octospim_p1_io3_pa6 {
				pinmux = <STM32_PINMUX('A', 6, AF10)>;
				slew-rate = "very-high-speed";
			};

			/omit-if-no-ref/ octospim_p1_io2_pa7: octospim_p1_io2_pa7 {
				pinmux = <STM32_PINMUX('A', 7, AF10)>;
				slew-rate = "very-high-speed";
			};

			/omit-if-no-ref/ octospim_p2_ncs_pa12: octospim_p2_ncs_pa12 {
				pinmux = <STM32_PINMUX('A', 12, AF6)>;
				slew-rate = "very-high-speed";
			};

			/omit-if-no-ref/ octospim_p1_io1_pb0: octospim_p1_io1_pb0 {
				pinmux = <STM32_PINMUX('B', 0, AF10)>;
				slew-rate = "very-high-speed";
			};

			/omit-if-no-ref/ octospim_p1_io0_pb1: octospim_p1_io0_pb1 {
				pinmux = <STM32_PINMUX('B', 1, AF10)>;
				slew-rate = "very-high-speed";
			};

			/omit-if-no-ref/ octospim_p1_dqs_pb2: octospim_p1_dqs_pb2 {
				pinmux = <STM32_PINMUX('B', 2, AF10)>;
				slew-rate = "very-high-speed";
			};

			/omit-if-no-ref/ octospim_p1_nclk_pb5: octospim_p1_nclk_pb5 {
				pinmux = <STM32_PINMUX('B', 5, AF3)>;
				slew-rate = "very-high-speed";
			};

			/omit-if-no-ref/ octospim_p1_clk_pb10: octospim_p1_clk_pb10 {
				pinmux = <STM32_PINMUX('B', 10, AF10)>;
				slew-rate = "very-high-speed";
			};

			/omit-if-no-ref/ octospim_p1_ncs_pb11: octospim_p1_ncs_pb11 {
				pinmux = <STM32_PINMUX('B', 11, AF10)>;
				slew-rate = "very-high-speed";
			};

			/omit-if-no-ref/ octospim_p1_io7_pc0: octospim_p1_io7_pc0 {
				pinmux = <STM32_PINMUX('C', 0, AF3)>;
				slew-rate = "very-high-speed";
			};

			/omit-if-no-ref/ octospim_p1_io4_pc1: octospim_p1_io4_pc1 {
				pinmux = <STM32_PINMUX('C', 1, AF10)>;
				slew-rate = "very-high-speed";
			};

			/omit-if-no-ref/ octospim_p1_io5_pc2: octospim_p1_io5_pc2 {
				pinmux = <STM32_PINMUX('C', 2, AF10)>;
				slew-rate = "very-high-speed";
			};

			/omit-if-no-ref/ octospim_p1_io6_pc3: octospim_p1_io6_pc3 {
				pinmux = <STM32_PINMUX('C', 3, AF10)>;
				slew-rate = "very-high-speed";
			};

			/omit-if-no-ref/ octospim_p1_ncs_pc11: octospim_p1_ncs_pc11 {
				pinmux = <STM32_PINMUX('C', 11, AF5)>;
				slew-rate = "very-high-speed";
			};

			/omit-if-no-ref/ octospim_p2_ncs_pd3: octospim_p2_ncs_pd3 {
				pinmux = <STM32_PINMUX('D', 3, AF10)>;
				slew-rate = "very-high-speed";
			};

			/omit-if-no-ref/ octospim_p1_io4_pd4: octospim_p1_io4_pd4 {
				pinmux = <STM32_PINMUX('D', 4, AF10)>;
				slew-rate = "very-high-speed";
			};

			/omit-if-no-ref/ octospim_p1_io5_pd5: octospim_p1_io5_pd5 {
				pinmux = <STM32_PINMUX('D', 5, AF10)>;
				slew-rate = "very-high-speed";
			};

			/omit-if-no-ref/ octospim_p1_io6_pd6: octospim_p1_io6_pd6 {
				pinmux = <STM32_PINMUX('D', 6, AF10)>;
				slew-rate = "very-high-speed";
			};

			/omit-if-no-ref/ octospim_p1_io7_pd7: octospim_p1_io7_pd7 {
				pinmux = <STM32_PINMUX('D', 7, AF10)>;
				slew-rate = "very-high-speed";
			};

			/omit-if-no-ref/ octospim_p1_dqs_pe3: octospim_p1_dqs_pe3 {
				pinmux = <STM32_PINMUX('E', 3, AF3)>;
				slew-rate = "very-high-speed";
			};

			/omit-if-no-ref/ octospim_p1_nclk_pe9: octospim_p1_nclk_pe9 {
				pinmux = <STM32_PINMUX('E', 9, AF10)>;
				slew-rate = "very-high-speed";
			};

			/omit-if-no-ref/ octospim_p1_clk_pe10: octospim_p1_clk_pe10 {
				pinmux = <STM32_PINMUX('E', 10, AF10)>;
				slew-rate = "very-high-speed";
			};

			/omit-if-no-ref/ octospim_p1_ncs_pe11: octospim_p1_ncs_pe11 {
				pinmux = <STM32_PINMUX('E', 11, AF10)>;
				slew-rate = "very-high-speed";
			};

			/omit-if-no-ref/ octospim_p1_io0_pe12: octospim_p1_io0_pe12 {
				pinmux = <STM32_PINMUX('E', 12, AF10)>;
				slew-rate = "very-high-speed";
			};

			/omit-if-no-ref/ octospim_p1_io1_pe13: octospim_p1_io1_pe13 {
				pinmux = <STM32_PINMUX('E', 13, AF10)>;
				slew-rate = "very-high-speed";
			};

			/omit-if-no-ref/ octospim_p1_io2_pe14: octospim_p1_io2_pe14 {
				pinmux = <STM32_PINMUX('E', 14, AF10)>;
				slew-rate = "very-high-speed";
			};

			/omit-if-no-ref/ octospim_p1_io3_pe15: octospim_p1_io3_pe15 {
				pinmux = <STM32_PINMUX('E', 15, AF10)>;
				slew-rate = "very-high-speed";
			};

			/omit-if-no-ref/ octospim_p2_io0_pf0: octospim_p2_io0_pf0 {
				pinmux = <STM32_PINMUX('F', 0, AF5)>;
				slew-rate = "very-high-speed";
			};

			/omit-if-no-ref/ octospim_p2_io1_pf1: octospim_p2_io1_pf1 {
				pinmux = <STM32_PINMUX('F', 1, AF5)>;
				slew-rate = "very-high-speed";
			};

			/omit-if-no-ref/ octospim_p2_io2_pf2: octospim_p2_io2_pf2 {
				pinmux = <STM32_PINMUX('F', 2, AF5)>;
				slew-rate = "very-high-speed";
			};

			/omit-if-no-ref/ octospim_p2_io3_pf3: octospim_p2_io3_pf3 {
				pinmux = <STM32_PINMUX('F', 3, AF5)>;
				slew-rate = "very-high-speed";
			};

			/omit-if-no-ref/ octospim_p2_clk_pf4: octospim_p2_clk_pf4 {
				pinmux = <STM32_PINMUX('F', 4, AF5)>;
				slew-rate = "very-high-speed";
			};

			/omit-if-no-ref/ octospim_p2_nclk_pf5: octospim_p2_nclk_pf5 {
				pinmux = <STM32_PINMUX('F', 5, AF5)>;
				slew-rate = "very-high-speed";
			};

			/omit-if-no-ref/ octospim_p1_io3_pf6: octospim_p1_io3_pf6 {
				pinmux = <STM32_PINMUX('F', 6, AF10)>;
				slew-rate = "very-high-speed";
			};

			/omit-if-no-ref/ octospim_p2_ncs_pf6: octospim_p2_ncs_pf6 {
				pinmux = <STM32_PINMUX('F', 6, AF5)>;
				slew-rate = "very-high-speed";
			};

			/omit-if-no-ref/ octospim_p1_io2_pf7: octospim_p1_io2_pf7 {
				pinmux = <STM32_PINMUX('F', 7, AF10)>;
				slew-rate = "very-high-speed";
			};

			/omit-if-no-ref/ octospim_p1_io0_pf8: octospim_p1_io0_pf8 {
				pinmux = <STM32_PINMUX('F', 8, AF10)>;
				slew-rate = "very-high-speed";
			};

			/omit-if-no-ref/ octospim_p1_io1_pf9: octospim_p1_io1_pf9 {
				pinmux = <STM32_PINMUX('F', 9, AF10)>;
				slew-rate = "very-high-speed";
			};

			/omit-if-no-ref/ octospim_p1_clk_pf10: octospim_p1_clk_pf10 {
				pinmux = <STM32_PINMUX('F', 10, AF3)>;
				slew-rate = "very-high-speed";
			};

			/omit-if-no-ref/ octospim_p1_nclk_pf11: octospim_p1_nclk_pf11 {
				pinmux = <STM32_PINMUX('F', 11, AF3)>;
				slew-rate = "very-high-speed";
			};

			/omit-if-no-ref/ octospim_p2_dqs_pf12: octospim_p2_dqs_pf12 {
				pinmux = <STM32_PINMUX('F', 12, AF5)>;
				slew-rate = "very-high-speed";
			};

			/omit-if-no-ref/ octospim_p2_io4_pg0: octospim_p2_io4_pg0 {
				pinmux = <STM32_PINMUX('G', 0, AF5)>;
				slew-rate = "very-high-speed";
			};

			/omit-if-no-ref/ octospim_p2_io5_pg1: octospim_p2_io5_pg1 {
				pinmux = <STM32_PINMUX('G', 1, AF5)>;
				slew-rate = "very-high-speed";
			};

			/omit-if-no-ref/ octospim_p1_dqs_pg6: octospim_p1_dqs_pg6 {
				pinmux = <STM32_PINMUX('G', 6, AF3)>;
				slew-rate = "very-high-speed";
			};

			/omit-if-no-ref/ octospim_p2_dqs_pg7: octospim_p2_dqs_pg7 {
				pinmux = <STM32_PINMUX('G', 7, AF5)>;
				slew-rate = "very-high-speed";
			};

			/omit-if-no-ref/ octospim_p2_io6_pg9: octospim_p2_io6_pg9 {
				pinmux = <STM32_PINMUX('G', 9, AF5)>;
				slew-rate = "very-high-speed";
			};

			/omit-if-no-ref/ octospim_p2_io7_pg10: octospim_p2_io7_pg10 {
				pinmux = <STM32_PINMUX('G', 10, AF5)>;
				slew-rate = "very-high-speed";
			};

			/omit-if-no-ref/ octospim_p2_ncs_pg12: octospim_p2_ncs_pg12 {
				pinmux = <STM32_PINMUX('G', 12, AF5)>;
				slew-rate = "very-high-speed";
			};

			/omit-if-no-ref/ octospim_p2_dqs_pg15: octospim_p2_dqs_pg15 {
				pinmux = <STM32_PINMUX('G', 15, AF5)>;
				slew-rate = "very-high-speed";
			};

			/* RCC_MCO */

			/omit-if-no-ref/ rcc_mco_pa8: rcc_mco_pa8 {
				pinmux = <STM32_PINMUX('A', 8, AF0)>;
				slew-rate = "very-high-speed";
			};

			/* SAI_FS */

			/omit-if-no-ref/ sai1_fs_b_pa4: sai1_fs_b_pa4 {
				pinmux = <STM32_PINMUX('A', 4, AF13)>;
			};

			/omit-if-no-ref/ sai1_fs_a_pa9: sai1_fs_a_pa9 {
				pinmux = <STM32_PINMUX('A', 9, AF13)>;
			};

			/omit-if-no-ref/ sai1_fs_b_pa14: sai1_fs_b_pa14 {
				pinmux = <STM32_PINMUX('A', 14, AF13)>;
			};

			/omit-if-no-ref/ sai1_fs_b_pb6: sai1_fs_b_pb6 {
				pinmux = <STM32_PINMUX('B', 6, AF13)>;
			};

			/omit-if-no-ref/ sai1_fs_a_pb9: sai1_fs_a_pb9 {
				pinmux = <STM32_PINMUX('B', 9, AF13)>;
			};

			/omit-if-no-ref/ sai1_fs_a_pe4: sai1_fs_a_pe4 {
				pinmux = <STM32_PINMUX('E', 4, AF13)>;
			};

			/omit-if-no-ref/ sai1_fs_b_pe9: sai1_fs_b_pe9 {
				pinmux = <STM32_PINMUX('E', 9, AF13)>;
			};

			/omit-if-no-ref/ sai1_fs_b_pf9: sai1_fs_b_pf9 {
				pinmux = <STM32_PINMUX('F', 9, AF13)>;
			};

			/omit-if-no-ref/ sai2_fs_b_pa15: sai2_fs_b_pa15 {
				pinmux = <STM32_PINMUX('A', 15, AF13)>;
			};

			/omit-if-no-ref/ sai2_fs_a_pc0: sai2_fs_a_pc0 {
				pinmux = <STM32_PINMUX('C', 0, AF13)>;
			};

			/omit-if-no-ref/ sai2_fs_a_pd12: sai2_fs_a_pd12 {
				pinmux = <STM32_PINMUX('D', 12, AF13)>;
			};

			/omit-if-no-ref/ sai2_fs_b_pg3: sai2_fs_b_pg3 {
				pinmux = <STM32_PINMUX('G', 3, AF13)>;
			};

			/omit-if-no-ref/ sai2_fs_a_pg10: sai2_fs_a_pg10 {
				pinmux = <STM32_PINMUX('G', 10, AF13)>;
			};

			/* SAI_MCLK */

			/omit-if-no-ref/ sai1_mclk_a_pa3: sai1_mclk_a_pa3 {
				pinmux = <STM32_PINMUX('A', 3, AF13)>;
				slew-rate = "very-high-speed";
			};

			/omit-if-no-ref/ sai1_mclk_b_pb4: sai1_mclk_b_pb4 {
				pinmux = <STM32_PINMUX('B', 4, AF13)>;
				slew-rate = "very-high-speed";
			};

			/omit-if-no-ref/ sai1_mclk_a_pb8: sai1_mclk_a_pb8 {
				pinmux = <STM32_PINMUX('B', 8, AF13)>;
				slew-rate = "very-high-speed";
			};

			/omit-if-no-ref/ sai1_mclk_a_pe2: sai1_mclk_a_pe2 {
				pinmux = <STM32_PINMUX('E', 2, AF13)>;
				slew-rate = "very-high-speed";
			};

			/omit-if-no-ref/ sai1_mclk_b_pe10: sai1_mclk_b_pe10 {
				pinmux = <STM32_PINMUX('E', 10, AF13)>;
				slew-rate = "very-high-speed";
			};

			/omit-if-no-ref/ sai1_mclk_b_pf7: sai1_mclk_b_pf7 {
				pinmux = <STM32_PINMUX('F', 7, AF13)>;
				slew-rate = "very-high-speed";
			};

			/omit-if-no-ref/ sai1_mclk_a_pg7: sai1_mclk_a_pg7 {
				pinmux = <STM32_PINMUX('G', 7, AF13)>;
				slew-rate = "very-high-speed";
			};

			/omit-if-no-ref/ sai2_mclk_a_pb14: sai2_mclk_a_pb14 {
				pinmux = <STM32_PINMUX('B', 14, AF13)>;
				slew-rate = "very-high-speed";
			};

			/omit-if-no-ref/ sai2_mclk_a_pc6: sai2_mclk_a_pc6 {
				pinmux = <STM32_PINMUX('C', 6, AF13)>;
				slew-rate = "very-high-speed";
			};

			/omit-if-no-ref/ sai2_mclk_b_pc7: sai2_mclk_b_pc7 {
				pinmux = <STM32_PINMUX('C', 7, AF13)>;
				slew-rate = "very-high-speed";
			};

			/omit-if-no-ref/ sai2_mclk_b_pc11: sai2_mclk_b_pc11 {
				pinmux = <STM32_PINMUX('C', 11, AF13)>;
				slew-rate = "very-high-speed";
			};

			/omit-if-no-ref/ sai2_mclk_a_pd9: sai2_mclk_a_pd9 {
				pinmux = <STM32_PINMUX('D', 9, AF13)>;
				slew-rate = "very-high-speed";
			};

			/omit-if-no-ref/ sai2_mclk_b_pg4: sai2_mclk_b_pg4 {
				pinmux = <STM32_PINMUX('G', 4, AF13)>;
				slew-rate = "very-high-speed";
			};

			/* SAI_SCK */

			/omit-if-no-ref/ sai1_sck_a_pa8: sai1_sck_a_pa8 {
				pinmux = <STM32_PINMUX('A', 8, AF13)>;
				slew-rate = "very-high-speed";
			};

			/omit-if-no-ref/ sai1_sck_b_pb3: sai1_sck_b_pb3 {
				pinmux = <STM32_PINMUX('B', 3, AF13)>;
				slew-rate = "very-high-speed";
			};

			/omit-if-no-ref/ sai1_sck_a_pb10: sai1_sck_a_pb10 {
				pinmux = <STM32_PINMUX('B', 10, AF13)>;
				slew-rate = "very-high-speed";
			};

			/omit-if-no-ref/ sai1_sck_a_pe5: sai1_sck_a_pe5 {
				pinmux = <STM32_PINMUX('E', 5, AF13)>;
				slew-rate = "very-high-speed";
			};

			/omit-if-no-ref/ sai1_sck_b_pe8: sai1_sck_b_pe8 {
				pinmux = <STM32_PINMUX('E', 8, AF13)>;
				slew-rate = "very-high-speed";
			};

			/omit-if-no-ref/ sai1_sck_b_pf8: sai1_sck_b_pf8 {
				pinmux = <STM32_PINMUX('F', 8, AF13)>;
				slew-rate = "very-high-speed";
			};

			/omit-if-no-ref/ sai2_sck_a_pb13: sai2_sck_a_pb13 {
				pinmux = <STM32_PINMUX('B', 13, AF13)>;
				slew-rate = "very-high-speed";
			};

			/omit-if-no-ref/ sai2_sck_b_pc10: sai2_sck_b_pc10 {
				pinmux = <STM32_PINMUX('C', 10, AF13)>;
				slew-rate = "very-high-speed";
			};

			/omit-if-no-ref/ sai2_sck_a_pd10: sai2_sck_a_pd10 {
				pinmux = <STM32_PINMUX('D', 10, AF13)>;
				slew-rate = "very-high-speed";
			};

			/omit-if-no-ref/ sai2_sck_b_pg2: sai2_sck_b_pg2 {
				pinmux = <STM32_PINMUX('G', 2, AF13)>;
				slew-rate = "very-high-speed";
			};

			/omit-if-no-ref/ sai2_sck_a_pg9: sai2_sck_a_pg9 {
				pinmux = <STM32_PINMUX('G', 9, AF13)>;
				slew-rate = "very-high-speed";
			};

			/* SAI_SD */

			/omit-if-no-ref/ sai1_sd_a_pa10: sai1_sd_a_pa10 {
				pinmux = <STM32_PINMUX('A', 10, AF13)>;
			};

			/omit-if-no-ref/ sai1_sd_b_pa13: sai1_sd_b_pa13 {
				pinmux = <STM32_PINMUX('A', 13, AF13)>;
			};

			/omit-if-no-ref/ sai1_sd_b_pb5: sai1_sd_b_pb5 {
				pinmux = <STM32_PINMUX('B', 5, AF13)>;
			};

			/omit-if-no-ref/ sai1_sd_a_pc1: sai1_sd_a_pc1 {
				pinmux = <STM32_PINMUX('C', 1, AF13)>;
			};

			/omit-if-no-ref/ sai1_sd_a_pc3: sai1_sd_a_pc3 {
				pinmux = <STM32_PINMUX('C', 3, AF13)>;
			};

			/omit-if-no-ref/ sai1_sd_a_pd6: sai1_sd_a_pd6 {
				pinmux = <STM32_PINMUX('D', 6, AF13)>;
			};

			/omit-if-no-ref/ sai1_sd_b_pe3: sai1_sd_b_pe3 {
				pinmux = <STM32_PINMUX('E', 3, AF13)>;
			};

			/omit-if-no-ref/ sai1_sd_a_pe6: sai1_sd_a_pe6 {
				pinmux = <STM32_PINMUX('E', 6, AF13)>;
			};

			/omit-if-no-ref/ sai1_sd_b_pe7: sai1_sd_b_pe7 {
				pinmux = <STM32_PINMUX('E', 7, AF13)>;
			};

			/omit-if-no-ref/ sai1_sd_b_pf6: sai1_sd_b_pf6 {
				pinmux = <STM32_PINMUX('F', 6, AF13)>;
			};

			/omit-if-no-ref/ sai2_sd_a_pb15: sai2_sd_a_pb15 {
				pinmux = <STM32_PINMUX('B', 15, AF13)>;
			};

			/omit-if-no-ref/ sai2_sd_b_pc12: sai2_sd_b_pc12 {
				pinmux = <STM32_PINMUX('C', 12, AF13)>;
			};

			/omit-if-no-ref/ sai2_sd_a_pd11: sai2_sd_a_pd11 {
				pinmux = <STM32_PINMUX('D', 11, AF13)>;
			};

			/omit-if-no-ref/ sai2_sd_b_pg5: sai2_sd_b_pg5 {
				pinmux = <STM32_PINMUX('G', 5, AF13)>;
			};

			/omit-if-no-ref/ sai2_sd_a_pg12: sai2_sd_a_pg12 {
				pinmux = <STM32_PINMUX('G', 12, AF13)>;
			};

			/* SDMMC */

			/omit-if-no-ref/ sdmmc1_ckin_pb8: sdmmc1_ckin_pb8 {
				pinmux = <STM32_PINMUX('B', 8, AF8)>;
				bias-pull-up;
				slew-rate = "very-high-speed";
			};

			/omit-if-no-ref/ sdmmc1_d4_pb8: sdmmc1_d4_pb8 {
				pinmux = <STM32_PINMUX('B', 8, AF12)>;
				bias-pull-up;
				slew-rate = "very-high-speed";
			};

			/omit-if-no-ref/ sdmmc1_cdir_pb9: sdmmc1_cdir_pb9 {
				pinmux = <STM32_PINMUX('B', 9, AF8)>;
				bias-pull-up;
				slew-rate = "very-high-speed";
			};

			/omit-if-no-ref/ sdmmc1_d5_pb9: sdmmc1_d5_pb9 {
				pinmux = <STM32_PINMUX('B', 9, AF12)>;
				bias-pull-up;
				slew-rate = "very-high-speed";
			};

			/omit-if-no-ref/ sdmmc1_d5_pc0: sdmmc1_d5_pc0 {
				pinmux = <STM32_PINMUX('C', 0, AF12)>;
				bias-pull-up;
				slew-rate = "very-high-speed";
			};

			/omit-if-no-ref/ sdmmc1_d0dir_pc6: sdmmc1_d0dir_pc6 {
				pinmux = <STM32_PINMUX('C', 6, AF8)>;
				bias-pull-up;
				slew-rate = "very-high-speed";
			};

			/omit-if-no-ref/ sdmmc1_d6_pc6: sdmmc1_d6_pc6 {
				pinmux = <STM32_PINMUX('C', 6, AF12)>;
				bias-pull-up;
				slew-rate = "very-high-speed";
			};

			/omit-if-no-ref/ sdmmc1_d123dir_pc7: sdmmc1_d123dir_pc7 {
				pinmux = <STM32_PINMUX('C', 7, AF8)>;
				bias-pull-up;
				slew-rate = "very-high-speed";
			};

			/omit-if-no-ref/ sdmmc1_d7_pc7: sdmmc1_d7_pc7 {
				pinmux = <STM32_PINMUX('C', 7, AF12)>;
				bias-pull-up;
				slew-rate = "very-high-speed";
			};

			/omit-if-no-ref/ sdmmc1_d0_pc8: sdmmc1_d0_pc8 {
				pinmux = <STM32_PINMUX('C', 8, AF12)>;
				bias-pull-up;
				slew-rate = "very-high-speed";
			};

			/omit-if-no-ref/ sdmmc1_d1_pc9: sdmmc1_d1_pc9 {
				pinmux = <STM32_PINMUX('C', 9, AF12)>;
				bias-pull-up;
				slew-rate = "very-high-speed";
			};

			/omit-if-no-ref/ sdmmc1_d2_pc10: sdmmc1_d2_pc10 {
				pinmux = <STM32_PINMUX('C', 10, AF12)>;
				bias-pull-up;
				slew-rate = "very-high-speed";
			};

			/omit-if-no-ref/ sdmmc1_d3_pc11: sdmmc1_d3_pc11 {
				pinmux = <STM32_PINMUX('C', 11, AF12)>;
				bias-pull-up;
				slew-rate = "very-high-speed";
			};

			/omit-if-no-ref/ sdmmc1_ck_pc12: sdmmc1_ck_pc12 {
				pinmux = <STM32_PINMUX('C', 12, AF12)>;
				bias-pull-up;
				slew-rate = "very-high-speed";
			};

			/omit-if-no-ref/ sdmmc1_cmd_pd2: sdmmc1_cmd_pd2 {
				pinmux = <STM32_PINMUX('D', 2, AF12)>;
				bias-pull-up;
				slew-rate = "very-high-speed";
			};

			/omit-if-no-ref/ sdmmc2_cmd_pa0: sdmmc2_cmd_pa0 {
				pinmux = <STM32_PINMUX('A', 0, AF12)>;
				bias-pull-up;
				slew-rate = "very-high-speed";
			};

			/omit-if-no-ref/ sdmmc2_d2_pb3: sdmmc2_d2_pb3 {
				pinmux = <STM32_PINMUX('B', 3, AF12)>;
				bias-pull-up;
				slew-rate = "very-high-speed";
			};

			/omit-if-no-ref/ sdmmc2_d3_pb4: sdmmc2_d3_pb4 {
				pinmux = <STM32_PINMUX('B', 4, AF12)>;
				bias-pull-up;
				slew-rate = "very-high-speed";
			};

			/omit-if-no-ref/ sdmmc2_d4_pb8: sdmmc2_d4_pb8 {
				pinmux = <STM32_PINMUX('B', 8, AF11)>;
				bias-pull-up;
				slew-rate = "very-high-speed";
			};

			/omit-if-no-ref/ sdmmc2_d5_pb9: sdmmc2_d5_pb9 {
				pinmux = <STM32_PINMUX('B', 9, AF11)>;
				bias-pull-up;
				slew-rate = "very-high-speed";
			};

			/omit-if-no-ref/ sdmmc2_d0_pb14: sdmmc2_d0_pb14 {
				pinmux = <STM32_PINMUX('B', 14, AF12)>;
				bias-pull-up;
				slew-rate = "very-high-speed";
			};

			/omit-if-no-ref/ sdmmc2_d1_pb15: sdmmc2_d1_pb15 {
				pinmux = <STM32_PINMUX('B', 15, AF12)>;
				bias-pull-up;
				slew-rate = "very-high-speed";
			};

			/omit-if-no-ref/ sdmmc2_ck_pc1: sdmmc2_ck_pc1 {
				pinmux = <STM32_PINMUX('C', 1, AF12)>;
				bias-pull-up;
				slew-rate = "very-high-speed";
			};

			/omit-if-no-ref/ sdmmc2_d6_pc6: sdmmc2_d6_pc6 {
				pinmux = <STM32_PINMUX('C', 6, AF11)>;
				bias-pull-up;
				slew-rate = "very-high-speed";
			};

			/omit-if-no-ref/ sdmmc2_d7_pc7: sdmmc2_d7_pc7 {
				pinmux = <STM32_PINMUX('C', 7, AF11)>;
				bias-pull-up;
				slew-rate = "very-high-speed";
			};

			/omit-if-no-ref/ sdmmc2_ck_pd6: sdmmc2_ck_pd6 {
				pinmux = <STM32_PINMUX('D', 6, AF11)>;
				bias-pull-up;
				slew-rate = "very-high-speed";
			};

			/omit-if-no-ref/ sdmmc2_cmd_pd7: sdmmc2_cmd_pd7 {
				pinmux = <STM32_PINMUX('D', 7, AF11)>;
				bias-pull-up;
				slew-rate = "very-high-speed";
			};

			/* SPI_MISO */

			/omit-if-no-ref/ spi1_miso_pa6: spi1_miso_pa6 {
				pinmux = <STM32_PINMUX('A', 6, AF5)>;
				bias-pull-down;
			};

			/omit-if-no-ref/ spi1_miso_pa11: spi1_miso_pa11 {
				pinmux = <STM32_PINMUX('A', 11, AF5)>;
				bias-pull-down;
			};

			/omit-if-no-ref/ spi1_miso_pb4: spi1_miso_pb4 {
				pinmux = <STM32_PINMUX('B', 4, AF5)>;
				bias-pull-down;
			};

			/omit-if-no-ref/ spi1_miso_pe14: spi1_miso_pe14 {
				pinmux = <STM32_PINMUX('E', 14, AF5)>;
				bias-pull-down;
			};

			/omit-if-no-ref/ spi1_miso_pg3: spi1_miso_pg3 {
				pinmux = <STM32_PINMUX('G', 3, AF5)>;
				bias-pull-down;
			};

			/omit-if-no-ref/ spi2_miso_pb14: spi2_miso_pb14 {
				pinmux = <STM32_PINMUX('B', 14, AF5)>;
				bias-pull-down;
			};

			/omit-if-no-ref/ spi2_miso_pc2: spi2_miso_pc2 {
				pinmux = <STM32_PINMUX('C', 2, AF5)>;
				bias-pull-down;
			};

			/omit-if-no-ref/ spi2_miso_pd3: spi2_miso_pd3 {
				pinmux = <STM32_PINMUX('D', 3, AF5)>;
				bias-pull-down;
			};

			/omit-if-no-ref/ spi3_miso_pb4: spi3_miso_pb4 {
				pinmux = <STM32_PINMUX('B', 4, AF6)>;
				bias-pull-down;
			};

			/omit-if-no-ref/ spi3_miso_pc11: spi3_miso_pc11 {
				pinmux = <STM32_PINMUX('C', 11, AF6)>;
				bias-pull-down;
			};

			/omit-if-no-ref/ spi3_miso_pg10: spi3_miso_pg10 {
				pinmux = <STM32_PINMUX('G', 10, AF6)>;
				bias-pull-down;
			};

			/* SPI_MOSI */

			/omit-if-no-ref/ spi1_mosi_pa7: spi1_mosi_pa7 {
				pinmux = <STM32_PINMUX('A', 7, AF5)>;
				bias-pull-down;
			};

			/omit-if-no-ref/ spi1_mosi_pa12: spi1_mosi_pa12 {
				pinmux = <STM32_PINMUX('A', 12, AF5)>;
				bias-pull-down;
			};

			/omit-if-no-ref/ spi1_mosi_pb5: spi1_mosi_pb5 {
				pinmux = <STM32_PINMUX('B', 5, AF5)>;
				bias-pull-down;
			};

			/omit-if-no-ref/ spi1_mosi_pe15: spi1_mosi_pe15 {
				pinmux = <STM32_PINMUX('E', 15, AF5)>;
				bias-pull-down;
			};

			/omit-if-no-ref/ spi1_mosi_pg4: spi1_mosi_pg4 {
				pinmux = <STM32_PINMUX('G', 4, AF5)>;
				bias-pull-down;
			};

			/omit-if-no-ref/ spi2_mosi_pb15: spi2_mosi_pb15 {
				pinmux = <STM32_PINMUX('B', 15, AF5)>;
				bias-pull-down;
			};

			/omit-if-no-ref/ spi2_mosi_pc1: spi2_mosi_pc1 {
				pinmux = <STM32_PINMUX('C', 1, AF3)>;
				bias-pull-down;
			};

			/omit-if-no-ref/ spi2_mosi_pc3: spi2_mosi_pc3 {
				pinmux = <STM32_PINMUX('C', 3, AF5)>;
				bias-pull-down;
			};

			/omit-if-no-ref/ spi2_mosi_pd4: spi2_mosi_pd4 {
				pinmux = <STM32_PINMUX('D', 4, AF5)>;
				bias-pull-down;
			};

			/omit-if-no-ref/ spi3_mosi_pb5: spi3_mosi_pb5 {
				pinmux = <STM32_PINMUX('B', 5, AF6)>;
				bias-pull-down;
			};

			/omit-if-no-ref/ spi3_mosi_pc12: spi3_mosi_pc12 {
				pinmux = <STM32_PINMUX('C', 12, AF6)>;
				bias-pull-down;
			};

			/omit-if-no-ref/ spi3_mosi_pd6: spi3_mosi_pd6 {
				pinmux = <STM32_PINMUX('D', 6, AF5)>;
				bias-pull-down;
			};

			/* SPI_NSS */

			/omit-if-no-ref/ spi1_nss_pa4: spi1_nss_pa4 {
				pinmux = <STM32_PINMUX('A', 4, AF5)>;
				bias-pull-up;
			};

			/omit-if-no-ref/ spi1_nss_pa15: spi1_nss_pa15 {
				pinmux = <STM32_PINMUX('A', 15, AF5)>;
				bias-pull-up;
			};

			/omit-if-no-ref/ spi1_nss_pb0: spi1_nss_pb0 {
				pinmux = <STM32_PINMUX('B', 0, AF5)>;
				bias-pull-up;
			};

			/omit-if-no-ref/ spi1_nss_pe12: spi1_nss_pe12 {
				pinmux = <STM32_PINMUX('E', 12, AF5)>;
				bias-pull-up;
			};

			/omit-if-no-ref/ spi1_nss_pg5: spi1_nss_pg5 {
				pinmux = <STM32_PINMUX('G', 5, AF5)>;
				bias-pull-up;
			};

			/omit-if-no-ref/ spi2_nss_pb9: spi2_nss_pb9 {
				pinmux = <STM32_PINMUX('B', 9, AF5)>;
				bias-pull-up;
			};

			/omit-if-no-ref/ spi2_nss_pd0: spi2_nss_pd0 {
				pinmux = <STM32_PINMUX('D', 0, AF5)>;
				bias-pull-up;
			};

			/omit-if-no-ref/ spi3_nss_pa4: spi3_nss_pa4 {
				pinmux = <STM32_PINMUX('A', 4, AF6)>;
				bias-pull-up;
			};

			/omit-if-no-ref/ spi3_nss_pa15: spi3_nss_pa15 {
				pinmux = <STM32_PINMUX('A', 15, AF6)>;
				bias-pull-up;
			};

			/omit-if-no-ref/ spi3_nss_pg12: spi3_nss_pg12 {
				pinmux = <STM32_PINMUX('G', 12, AF6)>;
				bias-pull-up;
			};

			/* SPI_SCK */

			/omit-if-no-ref/ spi1_sck_pa1: spi1_sck_pa1 {
				pinmux = <STM32_PINMUX('A', 1, AF5)>;
				bias-pull-down;
				slew-rate = "very-high-speed";
			};

			/omit-if-no-ref/ spi1_sck_pa5: spi1_sck_pa5 {
				pinmux = <STM32_PINMUX('A', 5, AF5)>;
				bias-pull-down;
				slew-rate = "very-high-speed";
			};

			/omit-if-no-ref/ spi1_sck_pb3: spi1_sck_pb3 {
				pinmux = <STM32_PINMUX('B', 3, AF5)>;
				bias-pull-down;
				slew-rate = "very-high-speed";
			};

			/omit-if-no-ref/ spi1_sck_pe13: spi1_sck_pe13 {
				pinmux = <STM32_PINMUX('E', 13, AF5)>;
				bias-pull-down;
				slew-rate = "very-high-speed";
			};

			/omit-if-no-ref/ spi1_sck_pg2: spi1_sck_pg2 {
				pinmux = <STM32_PINMUX('G', 2, AF5)>;
				bias-pull-down;
				slew-rate = "very-high-speed";
			};

			/omit-if-no-ref/ spi2_sck_pa9: spi2_sck_pa9 {
				pinmux = <STM32_PINMUX('A', 9, AF3)>;
				bias-pull-down;
				slew-rate = "very-high-speed";
			};

			/omit-if-no-ref/ spi2_sck_pb10: spi2_sck_pb10 {
				pinmux = <STM32_PINMUX('B', 10, AF5)>;
				bias-pull-down;
				slew-rate = "very-high-speed";
			};

			/omit-if-no-ref/ spi2_sck_pb13: spi2_sck_pb13 {
				pinmux = <STM32_PINMUX('B', 13, AF5)>;
				bias-pull-down;
				slew-rate = "very-high-speed";
			};

			/omit-if-no-ref/ spi2_sck_pd1: spi2_sck_pd1 {
				pinmux = <STM32_PINMUX('D', 1, AF5)>;
				bias-pull-down;
				slew-rate = "very-high-speed";
			};

			/omit-if-no-ref/ spi2_sck_pd3: spi2_sck_pd3 {
				pinmux = <STM32_PINMUX('D', 3, AF3)>;
				bias-pull-down;
				slew-rate = "very-high-speed";
			};

			/omit-if-no-ref/ spi3_sck_pb3: spi3_sck_pb3 {
				pinmux = <STM32_PINMUX('B', 3, AF6)>;
				bias-pull-down;
				slew-rate = "very-high-speed";
			};

			/omit-if-no-ref/ spi3_sck_pc10: spi3_sck_pc10 {
				pinmux = <STM32_PINMUX('C', 10, AF6)>;
				bias-pull-down;
				slew-rate = "very-high-speed";
			};

			/omit-if-no-ref/ spi3_sck_pg9: spi3_sck_pg9 {
				pinmux = <STM32_PINMUX('G', 9, AF6)>;
				bias-pull-down;
				slew-rate = "very-high-speed";
			};

			/* TIM_BKIN */

			/omit-if-no-ref/ tim1_bkin_pa6: tim1_bkin_pa6 {
				pinmux = <STM32_PINMUX('A', 6, AF1)>;
			};

			/omit-if-no-ref/ tim1_bkin2_pa11: tim1_bkin2_pa11 {
				pinmux = <STM32_PINMUX('A', 11, AF2)>;
			};

			/omit-if-no-ref/ tim1_bkin2_pe14: tim1_bkin2_pe14 {
				pinmux = <STM32_PINMUX('E', 14, AF2)>;
			};

			/omit-if-no-ref/ tim1_bkin_pe15: tim1_bkin_pe15 {
				pinmux = <STM32_PINMUX('E', 15, AF1)>;
			};

			/omit-if-no-ref/ tim15_bkin_pa9: tim15_bkin_pa9 {
				pinmux = <STM32_PINMUX('A', 9, AF14)>;
			};

			/omit-if-no-ref/ tim16_bkin_pb5: tim16_bkin_pb5 {
				pinmux = <STM32_PINMUX('B', 5, AF14)>;
			};

			/omit-if-no-ref/ tim17_bkin_pa10: tim17_bkin_pa10 {
				pinmux = <STM32_PINMUX('A', 10, AF14)>;
			};

			/omit-if-no-ref/ tim17_bkin_pb4: tim17_bkin_pb4 {
				pinmux = <STM32_PINMUX('B', 4, AF14)>;
			};

			/omit-if-no-ref/ tim8_bkin_pa6: tim8_bkin_pa6 {
				pinmux = <STM32_PINMUX('A', 6, AF3)>;
			};

			/omit-if-no-ref/ tim8_bkin2_pb6: tim8_bkin2_pb6 {
				pinmux = <STM32_PINMUX('B', 6, AF3)>;
			};

			/omit-if-no-ref/ tim8_bkin_pb7: tim8_bkin_pb7 {
				pinmux = <STM32_PINMUX('B', 7, AF3)>;
			};

			/omit-if-no-ref/ tim8_bkin2_pc9: tim8_bkin2_pc9 {
				pinmux = <STM32_PINMUX('C', 9, AF1)>;
			};

			/* TIM_CH / TIM_CHN */

			/omit-if-no-ref/ tim1_ch1n_pa7: tim1_ch1n_pa7 {
				pinmux = <STM32_PINMUX('A', 7, AF1)>;
			};

			/omit-if-no-ref/ tim1_ch1_pa8: tim1_ch1_pa8 {
				pinmux = <STM32_PINMUX('A', 8, AF1)>;
			};

			/omit-if-no-ref/ tim1_ch2_pa9: tim1_ch2_pa9 {
				pinmux = <STM32_PINMUX('A', 9, AF1)>;
			};

			/omit-if-no-ref/ tim1_ch3_pa10: tim1_ch3_pa10 {
				pinmux = <STM32_PINMUX('A', 10, AF1)>;
			};

			/omit-if-no-ref/ tim1_ch4_pa11: tim1_ch4_pa11 {
				pinmux = <STM32_PINMUX('A', 11, AF1)>;
			};

			/omit-if-no-ref/ tim1_ch2n_pb0: tim1_ch2n_pb0 {
				pinmux = <STM32_PINMUX('B', 0, AF1)>;
			};

			/omit-if-no-ref/ tim1_ch3n_pb1: tim1_ch3n_pb1 {
				pinmux = <STM32_PINMUX('B', 1, AF1)>;
			};

			/omit-if-no-ref/ tim1_ch1n_pb13: tim1_ch1n_pb13 {
				pinmux = <STM32_PINMUX('B', 13, AF1)>;
			};

			/omit-if-no-ref/ tim1_ch2n_pb14: tim1_ch2n_pb14 {
				pinmux = <STM32_PINMUX('B', 14, AF1)>;
			};

			/omit-if-no-ref/ tim1_ch3n_pb15: tim1_ch3n_pb15 {
				pinmux = <STM32_PINMUX('B', 15, AF1)>;
			};

			/omit-if-no-ref/ tim1_ch1n_pe8: tim1_ch1n_pe8 {
				pinmux = <STM32_PINMUX('E', 8, AF1)>;
			};

			/omit-if-no-ref/ tim1_ch1_pe9: tim1_ch1_pe9 {
				pinmux = <STM32_PINMUX('E', 9, AF1)>;
			};

			/omit-if-no-ref/ tim1_ch2n_pe10: tim1_ch2n_pe10 {
				pinmux = <STM32_PINMUX('E', 10, AF1)>;
			};

			/omit-if-no-ref/ tim1_ch2_pe11: tim1_ch2_pe11 {
				pinmux = <STM32_PINMUX('E', 11, AF1)>;
			};

			/omit-if-no-ref/ tim1_ch3n_pe12: tim1_ch3n_pe12 {
				pinmux = <STM32_PINMUX('E', 12, AF1)>;
			};

			/omit-if-no-ref/ tim1_ch3_pe13: tim1_ch3_pe13 {
				pinmux = <STM32_PINMUX('E', 13, AF1)>;
			};

			/omit-if-no-ref/ tim1_ch4_pe14: tim1_ch4_pe14 {
				pinmux = <STM32_PINMUX('E', 14, AF1)>;
			};

			/omit-if-no-ref/ tim1_ch4n_pe15: tim1_ch4n_pe15 {
				pinmux = <STM32_PINMUX('E', 15, AF3)>;
			};

			/omit-if-no-ref/ tim2_ch1_pa0: tim2_ch1_pa0 {
				pinmux = <STM32_PINMUX('A', 0, AF1)>;
			};

			/omit-if-no-ref/ tim2_ch2_pa1: tim2_ch2_pa1 {
				pinmux = <STM32_PINMUX('A', 1, AF1)>;
			};

			/omit-if-no-ref/ tim2_ch3_pa2: tim2_ch3_pa2 {
				pinmux = <STM32_PINMUX('A', 2, AF1)>;
			};

			/omit-if-no-ref/ tim2_ch4_pa3: tim2_ch4_pa3 {
				pinmux = <STM32_PINMUX('A', 3, AF1)>;
			};

			/omit-if-no-ref/ tim2_ch1_pa5: tim2_ch1_pa5 {
				pinmux = <STM32_PINMUX('A', 5, AF1)>;
			};

			/omit-if-no-ref/ tim2_ch1_pa15: tim2_ch1_pa15 {
				pinmux = <STM32_PINMUX('A', 15, AF1)>;
			};

			/omit-if-no-ref/ tim2_ch2_pb3: tim2_ch2_pb3 {
				pinmux = <STM32_PINMUX('B', 3, AF1)>;
			};

			/omit-if-no-ref/ tim2_ch3_pb10: tim2_ch3_pb10 {
				pinmux = <STM32_PINMUX('B', 10, AF1)>;
			};

			/omit-if-no-ref/ tim2_ch4_pb11: tim2_ch4_pb11 {
				pinmux = <STM32_PINMUX('B', 11, AF1)>;
			};

			/omit-if-no-ref/ tim3_ch1_pa6: tim3_ch1_pa6 {
				pinmux = <STM32_PINMUX('A', 6, AF2)>;
			};

			/omit-if-no-ref/ tim3_ch2_pa7: tim3_ch2_pa7 {
				pinmux = <STM32_PINMUX('A', 7, AF2)>;
			};

			/omit-if-no-ref/ tim3_ch3_pb0: tim3_ch3_pb0 {
				pinmux = <STM32_PINMUX('B', 0, AF2)>;
			};

			/omit-if-no-ref/ tim3_ch4_pb1: tim3_ch4_pb1 {
				pinmux = <STM32_PINMUX('B', 1, AF2)>;
			};

			/omit-if-no-ref/ tim3_ch1_pb4: tim3_ch1_pb4 {
				pinmux = <STM32_PINMUX('B', 4, AF2)>;
			};

			/omit-if-no-ref/ tim3_ch2_pb5: tim3_ch2_pb5 {
				pinmux = <STM32_PINMUX('B', 5, AF2)>;
			};

			/omit-if-no-ref/ tim3_ch1_pc6: tim3_ch1_pc6 {
				pinmux = <STM32_PINMUX('C', 6, AF2)>;
			};

			/omit-if-no-ref/ tim3_ch2_pc7: tim3_ch2_pc7 {
				pinmux = <STM32_PINMUX('C', 7, AF2)>;
			};

			/omit-if-no-ref/ tim3_ch3_pc8: tim3_ch3_pc8 {
				pinmux = <STM32_PINMUX('C', 8, AF2)>;
			};

			/omit-if-no-ref/ tim3_ch4_pc9: tim3_ch4_pc9 {
				pinmux = <STM32_PINMUX('C', 9, AF2)>;
			};

			/omit-if-no-ref/ tim3_ch1_pe3: tim3_ch1_pe3 {
				pinmux = <STM32_PINMUX('E', 3, AF2)>;
			};

			/omit-if-no-ref/ tim3_ch2_pe4: tim3_ch2_pe4 {
				pinmux = <STM32_PINMUX('E', 4, AF2)>;
			};

			/omit-if-no-ref/ tim3_ch3_pe5: tim3_ch3_pe5 {
				pinmux = <STM32_PINMUX('E', 5, AF2)>;
			};

			/omit-if-no-ref/ tim3_ch4_pe6: tim3_ch4_pe6 {
				pinmux = <STM32_PINMUX('E', 6, AF2)>;
			};

			/omit-if-no-ref/ tim4_ch1_pb6: tim4_ch1_pb6 {
				pinmux = <STM32_PINMUX('B', 6, AF2)>;
			};

			/omit-if-no-ref/ tim4_ch2_pb7: tim4_ch2_pb7 {
				pinmux = <STM32_PINMUX('B', 7, AF2)>;
			};

			/omit-if-no-ref/ tim4_ch3_pb8: tim4_ch3_pb8 {
				pinmux = <STM32_PINMUX('B', 8, AF2)>;
			};

			/omit-if-no-ref/ tim4_ch4_pb9: tim4_ch4_pb9 {
				pinmux = <STM32_PINMUX('B', 9, AF2)>;
			};

			/omit-if-no-ref/ tim4_ch1_pd12: tim4_ch1_pd12 {
				pinmux = <STM32_PINMUX('D', 12, AF2)>;
			};

			/omit-if-no-ref/ tim4_ch2_pd13: tim4_ch2_pd13 {
				pinmux = <STM32_PINMUX('D', 13, AF2)>;
			};

			/omit-if-no-ref/ tim4_ch3_pd14: tim4_ch3_pd14 {
				pinmux = <STM32_PINMUX('D', 14, AF2)>;
			};

			/omit-if-no-ref/ tim4_ch4_pd15: tim4_ch4_pd15 {
				pinmux = <STM32_PINMUX('D', 15, AF2)>;
			};

			/omit-if-no-ref/ tim5_ch1_pa0: tim5_ch1_pa0 {
				pinmux = <STM32_PINMUX('A', 0, AF2)>;
			};

			/omit-if-no-ref/ tim15_ch1n_pa1: tim15_ch1n_pa1 {
				pinmux = <STM32_PINMUX('A', 1, AF14)>;
			};

			/omit-if-no-ref/ tim5_ch2_pa1: tim5_ch2_pa1 {
				pinmux = <STM32_PINMUX('A', 1, AF2)>;
			};

			/omit-if-no-ref/ tim15_ch1_pa2: tim15_ch1_pa2 {
				pinmux = <STM32_PINMUX('A', 2, AF14)>;
			};

			/omit-if-no-ref/ tim5_ch3_pa2: tim5_ch3_pa2 {
				pinmux = <STM32_PINMUX('A', 2, AF2)>;
			};

			/omit-if-no-ref/ tim15_ch2_pa3: tim15_ch2_pa3 {
				pinmux = <STM32_PINMUX('A', 3, AF14)>;
			};

			/omit-if-no-ref/ tim5_ch4_pa3: tim5_ch4_pa3 {
				pinmux = <STM32_PINMUX('A', 3, AF2)>;
			};

			/omit-if-no-ref/ tim15_ch1n_pb13: tim15_ch1n_pb13 {
				pinmux = <STM32_PINMUX('B', 13, AF14)>;
			};

			/omit-if-no-ref/ tim15_ch1_pb14: tim15_ch1_pb14 {
				pinmux = <STM32_PINMUX('B', 14, AF14)>;
			};

			/omit-if-no-ref/ tim15_ch2_pb15: tim15_ch2_pb15 {
				pinmux = <STM32_PINMUX('B', 15, AF14)>;
			};

			/omit-if-no-ref/ tim5_ch1_pf6: tim5_ch1_pf6 {
				pinmux = <STM32_PINMUX('F', 6, AF2)>;
			};

			/omit-if-no-ref/ tim5_ch2_pf7: tim5_ch2_pf7 {
				pinmux = <STM32_PINMUX('F', 7, AF2)>;
			};

			/omit-if-no-ref/ tim5_ch3_pf8: tim5_ch3_pf8 {
				pinmux = <STM32_PINMUX('F', 8, AF2)>;
			};

			/omit-if-no-ref/ tim15_ch1_pf9: tim15_ch1_pf9 {
				pinmux = <STM32_PINMUX('F', 9, AF14)>;
			};

			/omit-if-no-ref/ tim5_ch4_pf9: tim5_ch4_pf9 {
				pinmux = <STM32_PINMUX('F', 9, AF2)>;
			};

			/omit-if-no-ref/ tim15_ch2_pf10: tim15_ch2_pf10 {
				pinmux = <STM32_PINMUX('F', 10, AF14)>;
			};

			/omit-if-no-ref/ tim15_ch1n_pg9: tim15_ch1n_pg9 {
				pinmux = <STM32_PINMUX('G', 9, AF14)>;
			};

			/omit-if-no-ref/ tim15_ch1_pg10: tim15_ch1_pg10 {
				pinmux = <STM32_PINMUX('G', 10, AF14)>;
			};

			/omit-if-no-ref/ tim16_ch1_pa6: tim16_ch1_pa6 {
				pinmux = <STM32_PINMUX('A', 6, AF14)>;
			};

			/omit-if-no-ref/ tim16_ch1n_pb6: tim16_ch1n_pb6 {
				pinmux = <STM32_PINMUX('B', 6, AF14)>;
			};

			/omit-if-no-ref/ tim16_ch1_pb8: tim16_ch1_pb8 {
				pinmux = <STM32_PINMUX('B', 8, AF14)>;
			};

			/omit-if-no-ref/ tim16_ch1_pe0: tim16_ch1_pe0 {
				pinmux = <STM32_PINMUX('E', 0, AF14)>;
			};

			/omit-if-no-ref/ tim17_ch1_pa7: tim17_ch1_pa7 {
				pinmux = <STM32_PINMUX('A', 7, AF14)>;
			};

			/omit-if-no-ref/ tim17_ch1n_pb7: tim17_ch1n_pb7 {
				pinmux = <STM32_PINMUX('B', 7, AF14)>;
			};

			/omit-if-no-ref/ tim17_ch1_pb9: tim17_ch1_pb9 {
				pinmux = <STM32_PINMUX('B', 9, AF14)>;
			};

			/omit-if-no-ref/ tim17_ch1_pe1: tim17_ch1_pe1 {
				pinmux = <STM32_PINMUX('E', 1, AF14)>;
			};

			/omit-if-no-ref/ tim8_ch1n_pa5: tim8_ch1n_pa5 {
				pinmux = <STM32_PINMUX('A', 5, AF3)>;
			};

			/omit-if-no-ref/ tim8_ch1n_pa7: tim8_ch1n_pa7 {
				pinmux = <STM32_PINMUX('A', 7, AF3)>;
			};

			/omit-if-no-ref/ tim8_ch2n_pb0: tim8_ch2n_pb0 {
				pinmux = <STM32_PINMUX('B', 0, AF3)>;
			};

			/omit-if-no-ref/ tim8_ch3n_pb1: tim8_ch3n_pb1 {
				pinmux = <STM32_PINMUX('B', 1, AF3)>;
			};

			/omit-if-no-ref/ tim8_ch4n_pb2: tim8_ch4n_pb2 {
				pinmux = <STM32_PINMUX('B', 2, AF3)>;
			};

			/omit-if-no-ref/ tim8_ch2n_pb14: tim8_ch2n_pb14 {
				pinmux = <STM32_PINMUX('B', 14, AF3)>;
			};

			/omit-if-no-ref/ tim8_ch3n_pb15: tim8_ch3n_pb15 {
				pinmux = <STM32_PINMUX('B', 15, AF3)>;
			};

			/omit-if-no-ref/ tim8_ch1_pc6: tim8_ch1_pc6 {
				pinmux = <STM32_PINMUX('C', 6, AF3)>;
			};

			/omit-if-no-ref/ tim8_ch2_pc7: tim8_ch2_pc7 {
				pinmux = <STM32_PINMUX('C', 7, AF3)>;
			};

			/omit-if-no-ref/ tim8_ch3_pc8: tim8_ch3_pc8 {
				pinmux = <STM32_PINMUX('C', 8, AF3)>;
			};

			/omit-if-no-ref/ tim8_ch4_pc9: tim8_ch4_pc9 {
				pinmux = <STM32_PINMUX('C', 9, AF3)>;
			};

			/omit-if-no-ref/ tim8_ch4n_pd0: tim8_ch4n_pd0 {
				pinmux = <STM32_PINMUX('D', 0, AF3)>;
			};

			/* UART_CTS / USART_CTS / LPUART_CTS */

			/omit-if-no-ref/ lpuart1_cts_pa6: lpuart1_cts_pa6 {
				pinmux = <STM32_PINMUX('A', 6, AF8)>;
				bias-pull-up;
				drive-open-drain;
			};

			/omit-if-no-ref/ usart1_cts_pa11: usart1_cts_pa11 {
				pinmux = <STM32_PINMUX('A', 11, AF7)>;
				bias-pull-up;
				drive-open-drain;
			};

			/omit-if-no-ref/ usart1_cts_pb4: usart1_cts_pb4 {
				pinmux = <STM32_PINMUX('B', 4, AF7)>;
				bias-pull-up;
				drive-open-drain;
			};

			/omit-if-no-ref/ lpuart1_cts_pb13: lpuart1_cts_pb13 {
				pinmux = <STM32_PINMUX('B', 13, AF8)>;
				bias-pull-up;
				drive-open-drain;
			};

			/omit-if-no-ref/ lpuart1_cts_pg5: lpuart1_cts_pg5 {
				pinmux = <STM32_PINMUX('G', 5, AF8)>;
				bias-pull-up;
				drive-open-drain;
			};

			/omit-if-no-ref/ usart2_cts_pa0: usart2_cts_pa0 {
				pinmux = <STM32_PINMUX('A', 0, AF7)>;
				bias-pull-up;
				drive-open-drain;
			};

			/omit-if-no-ref/ usart2_cts_pd3: usart2_cts_pd3 {
				pinmux = <STM32_PINMUX('D', 3, AF7)>;
				bias-pull-up;
				drive-open-drain;
			};

			/omit-if-no-ref/ usart3_cts_pa6: usart3_cts_pa6 {
				pinmux = <STM32_PINMUX('A', 6, AF7)>;
				bias-pull-up;
				drive-open-drain;
			};

			/omit-if-no-ref/ usart3_cts_pb13: usart3_cts_pb13 {
				pinmux = <STM32_PINMUX('B', 13, AF7)>;
				bias-pull-up;
				drive-open-drain;
			};

			/omit-if-no-ref/ usart3_cts_pd11: usart3_cts_pd11 {
				pinmux = <STM32_PINMUX('D', 11, AF7)>;
				bias-pull-up;
				drive-open-drain;
			};

			/omit-if-no-ref/ uart4_cts_pb7: uart4_cts_pb7 {
				pinmux = <STM32_PINMUX('B', 7, AF8)>;
				bias-pull-up;
				drive-open-drain;
			};

			/omit-if-no-ref/ uart5_cts_pb5: uart5_cts_pb5 {
				pinmux = <STM32_PINMUX('B', 5, AF8)>;
				bias-pull-up;
				drive-open-drain;
			};

			/* UART_DE / USART_DE / LPUART_DE */

			/omit-if-no-ref/ usart1_de_pa12: usart1_de_pa12 {
				pinmux = <STM32_PINMUX('A', 12, AF7)>;
				drive-push-pull;
			};

			/omit-if-no-ref/ lpuart1_de_pb1: lpuart1_de_pb1 {
				pinmux = <STM32_PINMUX('B', 1, AF8)>;
				drive-push-pull;
			};

			/omit-if-no-ref/ usart1_de_pb3: usart1_de_pb3 {
				pinmux = <STM32_PINMUX('B', 3, AF7)>;
				drive-push-pull;
			};

			/omit-if-no-ref/ lpuart1_de_pg6: lpuart1_de_pg6 {
				pinmux = <STM32_PINMUX('G', 6, AF8)>;
				drive-push-pull;
			};

			/omit-if-no-ref/ usart1_de_pg12: usart1_de_pg12 {
				pinmux = <STM32_PINMUX('G', 12, AF7)>;
				drive-push-pull;
			};

			/omit-if-no-ref/ usart2_de_pa1: usart2_de_pa1 {
				pinmux = <STM32_PINMUX('A', 1, AF7)>;
				drive-push-pull;
			};

			/omit-if-no-ref/ usart2_de_pd4: usart2_de_pd4 {
				pinmux = <STM32_PINMUX('D', 4, AF7)>;
				drive-push-pull;
			};

			/omit-if-no-ref/ usart3_de_pa15: usart3_de_pa15 {
				pinmux = <STM32_PINMUX('A', 15, AF7)>;
				drive-push-pull;
			};

			/omit-if-no-ref/ usart3_de_pb1: usart3_de_pb1 {
				pinmux = <STM32_PINMUX('B', 1, AF7)>;
				drive-push-pull;
			};

			/omit-if-no-ref/ usart3_de_pb14: usart3_de_pb14 {
				pinmux = <STM32_PINMUX('B', 14, AF7)>;
				drive-push-pull;
			};

			/omit-if-no-ref/ usart3_de_pd2: usart3_de_pd2 {
				pinmux = <STM32_PINMUX('D', 2, AF7)>;
				drive-push-pull;
			};

			/omit-if-no-ref/ usart3_de_pd12: usart3_de_pd12 {
				pinmux = <STM32_PINMUX('D', 12, AF7)>;
				drive-push-pull;
			};

			/omit-if-no-ref/ uart4_de_pa15: uart4_de_pa15 {
				pinmux = <STM32_PINMUX('A', 15, AF8)>;
				drive-push-pull;
			};

			/omit-if-no-ref/ uart5_de_pb4: uart5_de_pb4 {
				pinmux = <STM32_PINMUX('B', 4, AF8)>;
				drive-push-pull;
			};

			/* UART_RTS / USART_RTS / LPUART_RTS */

			/omit-if-no-ref/ usart1_rts_pa12: usart1_rts_pa12 {
				pinmux = <STM32_PINMUX('A', 12, AF7)>;
				bias-pull-up;
				drive-open-drain;
			};

			/omit-if-no-ref/ lpuart1_rts_pb1: lpuart1_rts_pb1 {
				pinmux = <STM32_PINMUX('B', 1, AF8)>;
				bias-pull-up;
				drive-open-drain;
			};

			/omit-if-no-ref/ usart1_rts_pb3: usart1_rts_pb3 {
				pinmux = <STM32_PINMUX('B', 3, AF7)>;
				bias-pull-up;
				drive-open-drain;
			};

			/omit-if-no-ref/ lpuart1_rts_pg6: lpuart1_rts_pg6 {
				pinmux = <STM32_PINMUX('G', 6, AF8)>;
				bias-pull-up;
				drive-open-drain;
			};

			/omit-if-no-ref/ usart1_rts_pg12: usart1_rts_pg12 {
				pinmux = <STM32_PINMUX('G', 12, AF7)>;
				bias-pull-up;
				drive-open-drain;
			};

			/omit-if-no-ref/ usart2_rts_pa1: usart2_rts_pa1 {
				pinmux = <STM32_PINMUX('A', 1, AF7)>;
				bias-pull-up;
				drive-open-drain;
			};

			/omit-if-no-ref/ usart2_rts_pd4: usart2_rts_pd4 {
				pinmux = <STM32_PINMUX('D', 4, AF7)>;
				bias-pull-up;
				drive-open-drain;
			};

			/omit-if-no-ref/ usart3_rts_pa15: usart3_rts_pa15 {
				pinmux = <STM32_PINMUX('A', 15, AF7)>;
				bias-pull-up;
				drive-open-drain;
			};

			/omit-if-no-ref/ usart3_rts_pb1: usart3_rts_pb1 {
				pinmux = <STM32_PINMUX('B', 1, AF7)>;
				bias-pull-up;
				drive-open-drain;
			};

			/omit-if-no-ref/ usart3_rts_pb14: usart3_rts_pb14 {
				pinmux = <STM32_PINMUX('B', 14, AF7)>;
				bias-pull-up;
				drive-open-drain;
			};

			/omit-if-no-ref/ usart3_rts_pd2: usart3_rts_pd2 {
				pinmux = <STM32_PINMUX('D', 2, AF7)>;
				bias-pull-up;
				drive-open-drain;
			};

			/omit-if-no-ref/ usart3_rts_pd12: usart3_rts_pd12 {
				pinmux = <STM32_PINMUX('D', 12, AF7)>;
				bias-pull-up;
				drive-open-drain;
			};

			/omit-if-no-ref/ uart4_rts_pa15: uart4_rts_pa15 {
				pinmux = <STM32_PINMUX('A', 15, AF8)>;
				bias-pull-up;
				drive-open-drain;
			};

			/omit-if-no-ref/ uart5_rts_pb4: uart5_rts_pb4 {
				pinmux = <STM32_PINMUX('B', 4, AF8)>;
				bias-pull-up;
				drive-open-drain;
			};

			/* UART_RX / USART_RX / LPUART_RX */

			/omit-if-no-ref/ lpuart1_rx_pa3: lpuart1_rx_pa3 {
				pinmux = <STM32_PINMUX('A', 3, AF8)>;
			};

			/omit-if-no-ref/ usart1_rx_pa10: usart1_rx_pa10 {
				pinmux = <STM32_PINMUX('A', 10, AF7)>;
			};

			/omit-if-no-ref/ usart1_rx_pb7: usart1_rx_pb7 {
				pinmux = <STM32_PINMUX('B', 7, AF7)>;
			};

			/omit-if-no-ref/ lpuart1_rx_pb10: lpuart1_rx_pb10 {
				pinmux = <STM32_PINMUX('B', 10, AF8)>;
			};

			/omit-if-no-ref/ lpuart1_rx_pc0: lpuart1_rx_pc0 {
				pinmux = <STM32_PINMUX('C', 0, AF8)>;
			};

			/omit-if-no-ref/ lpuart1_rx_pg8: lpuart1_rx_pg8 {
				pinmux = <STM32_PINMUX('G', 8, AF8)>;
			};

			/omit-if-no-ref/ usart1_rx_pg10: usart1_rx_pg10 {
				pinmux = <STM32_PINMUX('G', 10, AF7)>;
			};

			/omit-if-no-ref/ usart2_rx_pa3: usart2_rx_pa3 {
				pinmux = <STM32_PINMUX('A', 3, AF7)>;
			};

			/omit-if-no-ref/ usart2_rx_pa15: usart2_rx_pa15 {
				pinmux = <STM32_PINMUX('A', 15, AF3)>;
			};

			/omit-if-no-ref/ usart2_rx_pd6: usart2_rx_pd6 {
				pinmux = <STM32_PINMUX('D', 6, AF7)>;
			};

			/omit-if-no-ref/ usart3_rx_pa5: usart3_rx_pa5 {
				pinmux = <STM32_PINMUX('A', 5, AF7)>;
			};

			/omit-if-no-ref/ usart3_rx_pb11: usart3_rx_pb11 {
				pinmux = <STM32_PINMUX('B', 11, AF7)>;
			};

			/omit-if-no-ref/ usart3_rx_pc11: usart3_rx_pc11 {
				pinmux = <STM32_PINMUX('C', 11, AF7)>;
			};

			/omit-if-no-ref/ usart3_rx_pd9: usart3_rx_pd9 {
				pinmux = <STM32_PINMUX('D', 9, AF7)>;
			};

			/omit-if-no-ref/ uart4_rx_pa1: uart4_rx_pa1 {
				pinmux = <STM32_PINMUX('A', 1, AF8)>;
			};

			/omit-if-no-ref/ uart4_rx_pc11: uart4_rx_pc11 {
				pinmux = <STM32_PINMUX('C', 11, AF8)>;
			};

			/omit-if-no-ref/ uart5_rx_pd2: uart5_rx_pd2 {
				pinmux = <STM32_PINMUX('D', 2, AF8)>;
			};

			/* UART_TX / USART_TX / LPUART_TX */

			/omit-if-no-ref/ lpuart1_tx_pa2: lpuart1_tx_pa2 {
				pinmux = <STM32_PINMUX('A', 2, AF8)>;
				bias-pull-up;
			};

			/omit-if-no-ref/ usart1_tx_pa9: usart1_tx_pa9 {
				pinmux = <STM32_PINMUX('A', 9, AF7)>;
				bias-pull-up;
			};

			/omit-if-no-ref/ usart1_tx_pb6: usart1_tx_pb6 {
				pinmux = <STM32_PINMUX('B', 6, AF7)>;
				bias-pull-up;
			};

			/omit-if-no-ref/ lpuart1_tx_pb11: lpuart1_tx_pb11 {
				pinmux = <STM32_PINMUX('B', 11, AF8)>;
				bias-pull-up;
			};

			/omit-if-no-ref/ lpuart1_tx_pc1: lpuart1_tx_pc1 {
				pinmux = <STM32_PINMUX('C', 1, AF8)>;
				bias-pull-up;
			};

			/omit-if-no-ref/ lpuart1_tx_pg7: lpuart1_tx_pg7 {
				pinmux = <STM32_PINMUX('G', 7, AF8)>;
				bias-pull-up;
			};

			/omit-if-no-ref/ usart1_tx_pg9: usart1_tx_pg9 {
				pinmux = <STM32_PINMUX('G', 9, AF7)>;
				bias-pull-up;
			};

			/omit-if-no-ref/ usart2_tx_pa2: usart2_tx_pa2 {
				pinmux = <STM32_PINMUX('A', 2, AF7)>;
				bias-pull-up;
			};

			/omit-if-no-ref/ usart2_tx_pd5: usart2_tx_pd5 {
				pinmux = <STM32_PINMUX('D', 5, AF7)>;
				bias-pull-up;
			};

			/omit-if-no-ref/ usart3_tx_pa7: usart3_tx_pa7 {
				pinmux = <STM32_PINMUX('A', 7, AF7)>;
				bias-pull-up;
			};

			/omit-if-no-ref/ usart3_tx_pb10: usart3_tx_pb10 {
				pinmux = <STM32_PINMUX('B', 10, AF7)>;
				bias-pull-up;
			};

			/omit-if-no-ref/ usart3_tx_pc10: usart3_tx_pc10 {
				pinmux = <STM32_PINMUX('C', 10, AF7)>;
				bias-pull-up;
			};

			/omit-if-no-ref/ usart3_tx_pd8: usart3_tx_pd8 {
				pinmux = <STM32_PINMUX('D', 8, AF7)>;
				bias-pull-up;
			};

			/omit-if-no-ref/ uart4_tx_pa0: uart4_tx_pa0 {
				pinmux = <STM32_PINMUX('A', 0, AF8)>;
				bias-pull-up;
			};

			/omit-if-no-ref/ uart4_tx_pc10: uart4_tx_pc10 {
				pinmux = <STM32_PINMUX('C', 10, AF8)>;
				bias-pull-up;
			};

			/omit-if-no-ref/ uart5_tx_pc12: uart5_tx_pc12 {
				pinmux = <STM32_PINMUX('C', 12, AF8)>;
				bias-pull-up;
			};

			/* UCPD */

			/omit-if-no-ref/ ucpd1_cc1_pa15: ucpd1_cc1_pa15 {
				pinmux = <STM32_PINMUX('A', 15, ANALOG)>;
			};

			/omit-if-no-ref/ ucpd1_cc2_pb15: ucpd1_cc2_pb15 {
				pinmux = <STM32_PINMUX('B', 15, ANALOG)>;
			};

			/* USB_OTG_FS */

			/omit-if-no-ref/ usb_otg_fs_sof_pa8: usb_otg_fs_sof_pa8 {
				pinmux = <STM32_PINMUX('A', 8, AF10)>;
			};

			/omit-if-no-ref/ usb_otg_fs_vbus_pa9: usb_otg_fs_vbus_pa9 {
				pinmux = <STM32_PINMUX('A', 9, ANALOG)>;
			};

			/omit-if-no-ref/ usb_otg_fs_id_pa10: usb_otg_fs_id_pa10 {
				pinmux = <STM32_PINMUX('A', 10, AF10)>;
			};

			/omit-if-no-ref/ usb_otg_fs_dm_pa11: usb_otg_fs_dm_pa11 {
				pinmux = <STM32_PINMUX('A', 11, AF10)>;
			};

			/omit-if-no-ref/ usb_otg_fs_dp_pa12: usb_otg_fs_dp_pa12 {
				pinmux = <STM32_PINMUX('A', 12, AF10)>;
			};

			/omit-if-no-ref/ usb_otg_fs_sof_pa14: usb_otg_fs_sof_pa14 {
				pinmux = <STM32_PINMUX('A', 14, AF10)>;
			};

		};
	};
};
